VERSION ""

NS_ :

BS_:

BU_: FUSION CCU EOP_R BMS MCU_F Shifter EOP_F MCU_R

BO_ 1173 GW_IVI2: 64 FUSION
 SG_ AVM_parking_cancel : 505|2@0+ (1,0) [0|3] "" Vector__XXX
 SG_ AVM_parking_excute : 507|2@0+ (1,0) [0|3] "" Vector__XXX
 SG_ AVM_OFF_Rec_Butt : 508|1@0+ (1,0) [0|1] "" Vector__XXX
 SG_ IVI_AGSCloseSW : 511|2@0+ (1,0) [0|3] "" Vector__XXX
 SG_ IVI_LVChrgFuncSW : 497|2@0+ (1,0) [0|3] "" Vector__XXX
 SG_ IVI_PwrLockSW : 499|2@0+ (1,0) [0|3] "" Vector__XXX
 SG_ IVI_CoastDwSW : 501|2@0+ (1,0) [0|3] "" Vector__XXX
 SG_ IVI_ActvDmpDisabSW : 503|2@0+ (1,0) [0|3] "" Vector__XXX
 SG_ Roll_Mode_SW_Cmd : 473|2@0+ (1,0) [0|3] "" Vector__XXX
 SG_ TCS_SW_Cmd : 475|2@0+ (1,0) [0|3] "" Vector__XXX
 SG_ SLIF_BUTT : 477|2@0+ (1,0) [0|2] "" Vector__XXX
 SG_ Roll_Eng_Mode : 478|1@0+ (1,0) [0|1] "" Vector__XXX
 SG_ SOC_Limit_Set : 468|5@0+ (2,50) [50|100] "%" BMS
 SG_ CDL_Lock_Butt : 469|1@0+ (1,0) [0|1] "" Vector__XXX
 SG_ CDL_Unlock_Butt : 470|1@0+ (1,0) [0|1] "" Vector__XXX
 SG_ SOC_ADJ_BUTT : 471|1@0+ (1,0) [0|1] "" BMS
 SG_ AC_Chg_Cur_Set : 462|7@0+ (1,5) [5|132] "A" CCU,BMS
 SG_ IVI_ISA_OffsetSpd : 451|4@0+ (1,0) [0|14] "" Vector__XXX
 SG_ RoomLampMode : 455|1@0+ (1,0) [0|1] "" Vector__XXX
 SG_ NAVI_SpeedLimit : 444|5@0+ (1,0) [0|31] "km/h" Vector__XXX
 SG_ NAVI_RoadClass : 447|3@0+ (1,0) [0|7] "" Vector__XXX
 SG_ NAVI_Tollgate : 427|12@0+ (1,0) [0|2000] "m" Vector__XXX
 SG_ NAVI_LinkClass : 431|4@0+ (1,0) [0|15] "" Vector__XXX
 SG_ NAVI_Tunnel : 411|12@0+ (1,0) [0|2000] "m" Vector__XXX
 SG_ NAVI_ForwardLinkLevel : 415|4@0+ (1,0) [0|15] "" Vector__XXX
 SG_ SenstivityPosition : 403|4@0+ (1,0) [0|15] "" Vector__XXX
 SG_ AVM_Parking_mode : 407|4@0+ (1,0) [0|15] "" Vector__XXX
 SG_ Hood_Latch_SW : 393|2@0+ (1,0) [0|3] "" Vector__XXX
 SG_ RCTA_BUTT : 396|2@0+ (1,0) [0|3] "" Vector__XXX
 SG_ IVI_Pwroff_req : 397|1@0+ (1,0) [0|1] "" Vector__XXX
 SG_ IVI_Trigger_req : 398|1@0+ (1,0) [0|1] "" Vector__XXX
 SG_ AVM_Err_STA : 399|1@0+ (1,0) [0|1] "" Vector__XXX
 SG_ NAVI_Distance_info : 375|24@0+ (1,0) [0|1.6777215E7] "m" Vector__XXX
 SG_ IVI_Mute_Sta : 360|1@0+ (1,0) [0|1] "" Vector__XXX
 SG_ IVI_PTG_USSta_SW : 361|1@0+ (1,0) [0|1] "" Vector__XXX
 SG_ IVI_WI_MAIN_SW : 362|1@0+ (1,0) [0|1] "" Vector__XXX
 SG_ IVI_RR_Def_Req : 363|1@0+ (1,0) [0|1] "" Vector__XXX
 SG_ IVI_Night_Mode_Sta : 364|1@0+ (1,0) [0|1] "" Vector__XXX
 SG_ IVI_Status : 365|1@0+ (1,0) [0|1] "" Vector__XXX
 SG_ LVDAMute_BUTT : 367|2@0+ (1,0) [0|3] "" Vector__XXX
 SG_ CAAS_Sw : 353|2@0+ (1,0) [0|3] "" Vector__XXX
 SG_ DSEAT_entryfun_set : 354|1@0+ (1,0) [0|1] "" Vector__XXX
 SG_ DSEAT_anti_set : 355|1@0+ (1,0) [0|1] "" Vector__XXX
 SG_ TPMS_Res_Butt : 357|1@0+ (1,0) [0|1] "" Vector__XXX
 SG_ FollowMeSW : 358|1@0+ (1,0) [0|1] "" Vector__XXX
 SG_ SetUnlockSingle : 359|1@0+ (1,0) [0|1] "" Vector__XXX
 SG_ IVI_PTG_Mode_SW : 345|2@0+ (1,0) [0|3] "" Vector__XXX
 SG_ IVI_PTG_Sta_SW : 347|2@0+ (1,0) [0|3] "" Vector__XXX
 SG_ SLG_Sw : 349|2@0+ (1,0) [0|3] "" Vector__XXX
 SG_ FS_Off_Sw : 351|2@0+ (1,0) [0|3] "" Vector__XXX
 SG_ PSEAT_vent_req : 338|3@0+ (1,0) [0|7] "" Vector__XXX
 SG_ FFogLampSW : 339|1@0+ (1,0) [0|1] "" Vector__XXX
 SG_ DSEAT_vent_req : 342|3@0+ (1,0) [0|7] "" Vector__XXX
 SG_ RFogLampSW : 343|1@0+ (1,0) [0|1] "" Vector__XXX
 SG_ MFRD_N_Bright_Req : 334|7@0+ (1,0) [0|100] "%" Vector__XXX
 SG_ User_p_download : 335|1@0+ (1,0) [0|1] "" Vector__XXX
 SG_ HeadLampSW : 321|2@0+ (1,0) [0|3] "" Vector__XXX
 SG_ NAVI_State : 323|2@0+ (1,0) [0|3] "" Vector__XXX
 SG_ Wifi_Sta_IVI_TBOX : 327|4@0+ (1,0) [0|15] "" Vector__XXX
 SG_ IVI_Panel_Y_Coor : 307|12@0+ (1,0) [0|4095] "" Vector__XXX
 SG_ IVI_Panel_X_Coor : 303|12@0+ (1,0) [0|4095] "" Vector__XXX
 SG_ NAVI_Cam_Dist_info : 295|8@0+ (1,0) [0|255] "m" Vector__XXX
 SG_ OFF_AC_MODE : 282|3@0+ (1,0) [0|7] "" Vector__XXX
 SG_ IVI_PW_Mode_Req : 284|2@0+ (1,0) [0|3] "" Vector__XXX
 SG_ User_p_upload : 285|1@0+ (1,0) [0|1] "" Vector__XXX
 SG_ CameraWrn : 286|1@0+ (1,0) [0|1] "" Vector__XXX
 SG_ Wifi_Reset : 287|1@0+ (1,0) [0|1] "" Vector__XXX
 SG_ NAVI_Direction_STA : 279|8@0+ (1,0) [0|255] "" Vector__XXX
 SG_ IVI_Screen : 269|6@0+ (1,0) [0|62] "" Vector__XXX
 SG_ TurnSwTimeSet : 271|2@0+ (1,0) [0|3] "" Vector__XXX
 SG_ Pressure_unit : 263|8@0+ (1,0) [0|255] "" Vector__XXX
 SG_ Time_system : 255|8@0+ (1,0) [0|255] "" Vector__XXX
 SG_ NAVI_Speed_Limit_A : 241|2@0+ (1,0) [0|3] "" Vector__XXX
 SG_ Temperature_unit : 242|1@0+ (1,0) [0|1] "" Vector__XXX
 SG_ Distance_unit : 243|1@0+ (1,0) [0|1] "" Vector__XXX
 SG_ ESC_SW_Cmd : 245|2@0+ (1,0) [0|3] "" Vector__XXX
 SG_ IVI_Panel_Act : 246|1@0+ (1,0) [0|1] "" Vector__XXX
 SG_ sigHvacRearReq : 247|1@0+ (1,0) [0|1] "" Vector__XXX
 SG_ FCWMute_BUTT : 233|2@0+ (1,0) [0|3] "" Vector__XXX
 SG_ LKA_BUTT : 235|2@0+ (1,0) [0|3] "" Vector__XXX
 SG_ ODAMute_BUTT : 237|2@0+ (1,0) [0|3] "" Vector__XXX
 SG_ LDWMute_BUTT : 239|2@0+ (1,0) [0|3] "" Vector__XXX
 SG_ BSDMute_BUTT : 225|2@0+ (1,0) [0|3] "" Vector__XXX
 SG_ sigWindDirZon3Req : 228|3@0+ (1,0) [0|7] "" Vector__XXX
 SG_ sigAirIntenZon3Req : 219|4@0+ (1,0) [0|15] "" Vector__XXX
 SG_ sigAirIntenZon1Req : 223|4@0+ (1,0) [0|15] "" Vector__XXX
 SG_ AEB_BUTT : 209|2@0+ (1,0) [0|3] "" Vector__XXX
 SG_ sigSetTempZon3Req : 215|6@0+ (0.5,17) [17|32] "Deg^C" Vector__XXX
 SG_ sigSetTempZon2Req : 205|6@0+ (0.5,17) [17|32] "Deg^C" Vector__XXX
 SG_ sigRecircReq : 206|1@0+ (1,0) [0|1] "" Vector__XXX
 SG_ sigHvacReq : 207|1@0+ (1,0) [0|1] "" Vector__XXX
 SG_ sigSetTempZon1Req : 197|6@0+ (0.5,17) [17|32] "Deg^C" Vector__XXX
 SG_ sigHvacFrontReq : 198|1@0+ (1,0) [0|1] "" Vector__XXX
 SG_ sigDfrstReq : 199|1@0+ (1,0) [0|1] "" Vector__XXX
 SG_ GPS_LAT : 167|32@0+ (1,0) [0|4.294967295E9] "SECOND" Vector__XXX
 SG_ GPS_LONG : 135|32@0+ (1,0) [0|4.294967295E9] "" Vector__XXX
 SG_ L_Drv_ControlCommand : 126|7@0+ (1,0) [0|127] "%" Vector__XXX
 SG_ TPMS_Cali_Butt : 127|1@0+ (1,0) [0|1] "" Vector__XXX
 SG_ L_Pas_ControlCommand : 118|7@0+ (1,0) [0|127] "%" Vector__XXX
 SG_ IVI_Unlock_Chg_req : 119|1@0+ (1,0) [0|1] "" BMS
 SG_ L_RLD_ControlCommand : 110|7@0+ (1,0) [0|127] "%" Vector__XXX
 SG_ IVI_Stop_Chg_req : 111|1@0+ (1,0) [0|1] "" BMS
 SG_ L_RRD_ControlCommand : 102|7@0+ (1,0) [0|127] "%" Vector__XXX
 SG_ IVI_Start_Chg_req : 103|1@0+ (1,0) [0|1] "" BMS
 SG_ METER_Malfunc_Sta : 89|2@0+ (1,0) [0|2] "" Vector__XXX
 SG_ sigFootReq : 90|1@0+ (1,0) [0|1] "" Vector__XXX
 SG_ sigFaceReq : 91|1@0+ (1,0) [0|1] "" Vector__XXX
 SG_ Sched_Chg_Start : 92|1@0+ (1,0) [0|1] "" BMS
 SG_ Sched_Chg_wake : 93|1@0+ (1,0) [0|1] "" Vector__XXX
 SG_ Sched_Chg_butt : 94|1@0+ (1,0) [0|1] "" BMS
 SG_ Sched_Chg_Stop : 95|1@0+ (1,0) [0|1] "" BMS
 SG_ Sched_Chg_limit : 84|5@0+ (2,50) [50|100] "%" BMS
 SG_ Walkaway_Lock_SW : 8|1@0+ (1,0) [0|1] "" Vector__XXX
 SG_ Approach_Unlock_SW : 9|1@0+ (1,0) [0|1] "" Vector__XXX
 SG_ FalseNPrevent_SW : 10|1@0+ (1,0) [0|1] "" Vector__XXX
 SG_ IVI_CreepSW_Req : 11|1@0+ (1,0) [0|1] "" Vector__XXX
 SG_ IVI_PTG_Open_Height : 14|3@0+ (1,0) [0|7] "" Vector__XXX
 SG_ IVI_Req_V2L : 15|1@0+ (1,0) [0|1] "" BMS
 SG_ Perd_V2L : 3|4@0+ (1,0) [0|15] "" BMS
 SG_ SOC_V2LLimit : 7|4@0+ (5,20) [20|80] "%" BMS

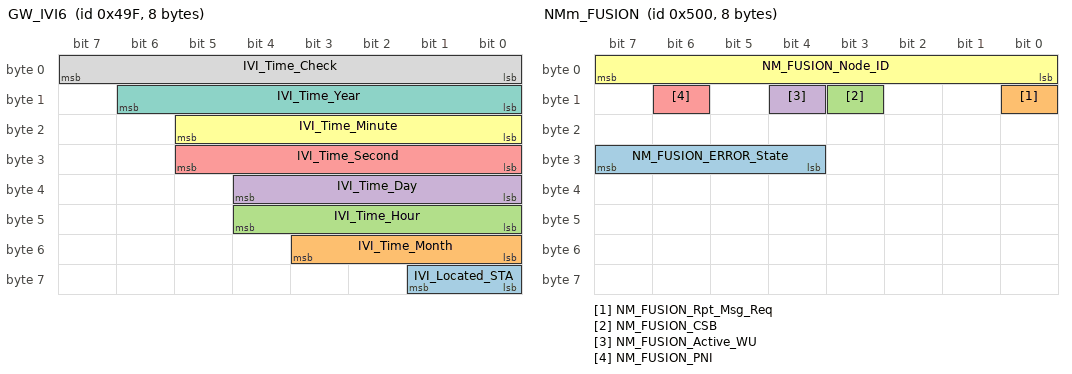
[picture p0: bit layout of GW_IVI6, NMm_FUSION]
BO_ 1183 GW_IVI6: 8 FUSION
 SG_ IVI_Located_STA : 57|2@0+ (1,0) [0|3] "" Vector__XXX
 SG_ IVI_Time_Month : 51|4@0+ (1,0) [0|12] "MONTH" CCU,EOP_R,BMS,MCU_F,Shifter,EOP_F,MCU_R
 SG_ IVI_Time_Hour : 44|5@0+ (1,0) [0|31] "HOUR" CCU,EOP_R,BMS,MCU_F,Shifter,EOP_F,MCU_R
 SG_ IVI_Time_Day : 36|5@0+ (1,0) [0|31] "DAY" CCU,EOP_R,BMS,MCU_F,Shifter,EOP_F,MCU_R
 SG_ IVI_Time_Second : 29|6@0+ (1,0) [0|63] "SECOND" CCU,EOP_R,BMS,MCU_F,Shifter,EOP_F,MCU_R
 SG_ IVI_Time_Minute : 21|6@0+ (1,0) [0|63] "MINUTE" CCU,EOP_R,BMS,MCU_F,Shifter,EOP_F,MCU_R
 SG_ IVI_Time_Year : 14|7@0+ (1,2000) [2000|2127] "YEAR" Vector__XXX
 SG_ IVI_Time_Check : 7|8@0+ (1,0) [0|255] "" CCU,EOP_R,BMS,Shifter,EOP_F

BO_ 1249 GW_TBOX3: 48 FUSION
 SG_ TBOX_SW_VER : 279|32@0+ (1,0) [0|4.294967295E9] "" Vector__XXX
 SG_ TBOX_HW_VER : 231|32@0+ (1,0) [0|4.294967295E9] "" Vector__XXX
 SG_ ReserveChargeOn_Minute : 221|6@0+ (1,0) [0|59] "MINUTE" BMS
 SG_ ReserveChargeOn_Hour : 210|5@0+ (1,0) [0|23] "HOUR" BMS
 SG_ ReserveChargeOn_Day : 215|5@0+ (1,0) [0|31] "DAY" BMS
 SG_ ReserveChargeOn_Month : 203|4@0+ (1,0) [0|12] "MONTH" BMS
 SG_ ReserveChargeOn_Year : 194|7@0+ (1,2000) [2000|2099] "YEAR" BMS
 SG_ ReserveChargeOFF_Minute : 189|6@0+ (1,0) [0|59] "MINUTE" BMS
 SG_ ReserveChargeOFF_Hour : 178|5@0+ (1,0) [0|23] "HOUR" BMS
 SG_ ReserveChargeOFF_Day : 183|5@0+ (1,0) [0|31] "DAY" BMS
 SG_ ReserveChargeOFF_Month : 171|4@0+ (1,0) [0|12] "MONTH" BMS
 SG_ ReserveChargeOFF_Year : 162|7@0+ (1,2000) [2000|2099] "YEAR" BMS
 SG_ Charge_Percent_Set : 159|8@0+ (1,0) [0|100] "%" BMS

BO_ 1280 NMm_FUSION: 8 FUSION
 SG_ NM_FUSION_ERROR_State : 31|4@0+ (1,0) [0|8] "" CCU,EOP_R,BMS,MCU_F,Shifter,EOP_F,MCU_R
 SG_ NM_FUSION_Rpt_Msg_Req : 8|1@0+ (1,0) [0|1] "" CCU,EOP_R,BMS,MCU_F,Shifter,EOP_F,MCU_R
 SG_ NM_FUSION_CSB : 11|1@0+ (1,0) [0|1] "" CCU,EOP_R,BMS,MCU_F,Shifter,EOP_F,MCU_R
 SG_ NM_FUSION_Active_WU : 12|1@0+ (1,0) [0|1] "" CCU,EOP_R,BMS,MCU_F,Shifter,EOP_F,MCU_R
 SG_ NM_FUSION_PNI : 14|1@0+ (1,0) [0|1] "" CCU,EOP_R,BMS,MCU_F,Shifter,EOP_F,MCU_R
 SG_ NM_FUSION_Node_ID : 7|8@0+ (1,0) [0|127] "" CCU,EOP_R,BMS,MCU_F,Shifter,EOP_F,MCU_R

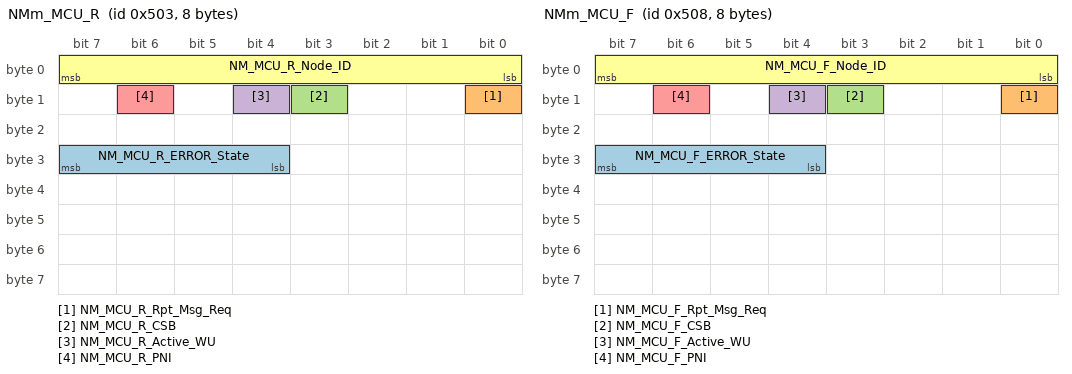
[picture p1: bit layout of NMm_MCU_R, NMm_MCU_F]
BO_ 1283 NMm_MCU_R: 8 MCU_R
 SG_ NM_MCU_R_ERROR_State : 31|4@0+ (1,0) [0|8] "" FUSION
 SG_ NM_MCU_R_Rpt_Msg_Req : 8|1@0+ (1,0) [0|1] "" FUSION
 SG_ NM_MCU_R_CSB : 11|1@0+ (1,0) [0|1] "" FUSION
 SG_ NM_MCU_R_Active_WU : 12|1@0+ (1,0) [0|1] "" FUSION
 SG_ NM_MCU_R_PNI : 14|1@0+ (1,0) [0|1] "" FUSION
 SG_ NM_MCU_R_Node_ID : 7|8@0+ (1,0) [0|127] "" FUSION

BO_ 1288 NMm_MCU_F: 8 MCU_F
 SG_ NM_MCU_F_ERROR_State : 31|4@0+ (1,0) [0|8] "" FUSION
 SG_ NM_MCU_F_Rpt_Msg_Req : 8|1@0+ (1,0) [0|1] "" FUSION
 SG_ NM_MCU_F_CSB : 11|1@0+ (1,0) [0|1] "" FUSION
 SG_ NM_MCU_F_Active_WU : 12|1@0+ (1,0) [0|1] "" FUSION
 SG_ NM_MCU_F_PNI : 14|1@0+ (1,0) [0|1] "" FUSION
 SG_ NM_MCU_F_Node_ID : 7|8@0+ (1,0) [0|127] "" FUSION

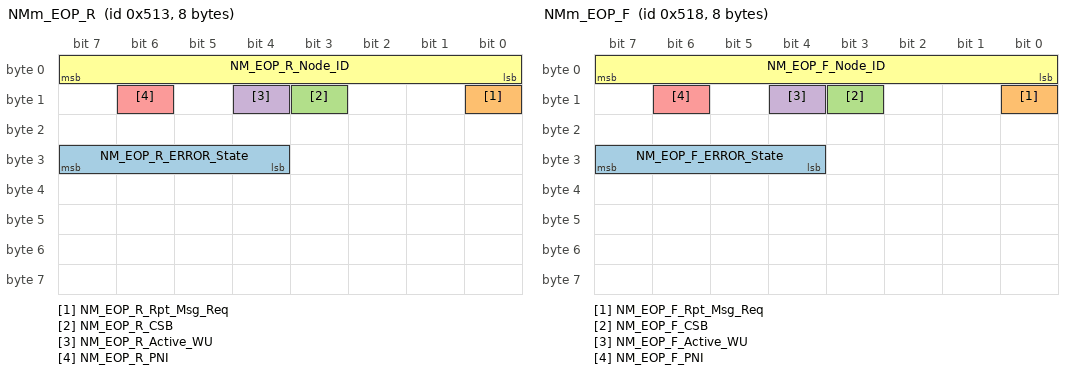
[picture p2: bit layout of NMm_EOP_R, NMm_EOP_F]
BO_ 1299 NMm_EOP_R: 8 EOP_R
 SG_ NM_EOP_R_ERROR_State : 31|4@0+ (1,0) [0|8] "" FUSION
 SG_ NM_EOP_R_Rpt_Msg_Req : 8|1@0+ (1,0) [0|1] "" FUSION
 SG_ NM_EOP_R_CSB : 11|1@0+ (1,0) [0|1] "" FUSION
 SG_ NM_EOP_R_Active_WU : 12|1@0+ (1,0) [0|1] "" FUSION
 SG_ NM_EOP_R_PNI : 14|1@0+ (1,0) [0|1] "" FUSION
 SG_ NM_EOP_R_Node_ID : 7|8@0+ (1,0) [0|127] "" FUSION

BO_ 1304 NMm_EOP_F: 8 EOP_F
 SG_ NM_EOP_F_ERROR_State : 31|4@0+ (1,0) [0|8] "" FUSION
 SG_ NM_EOP_F_Rpt_Msg_Req : 8|1@0+ (1,0) [0|1] "" FUSION
 SG_ NM_EOP_F_CSB : 11|1@0+ (1,0) [0|1] "" FUSION
 SG_ NM_EOP_F_Active_WU : 12|1@0+ (1,0) [0|1] "" FUSION
 SG_ NM_EOP_F_PNI : 14|1@0+ (1,0) [0|1] "" FUSION
 SG_ NM_EOP_F_Node_ID : 7|8@0+ (1,0) [0|127] "" FUSION

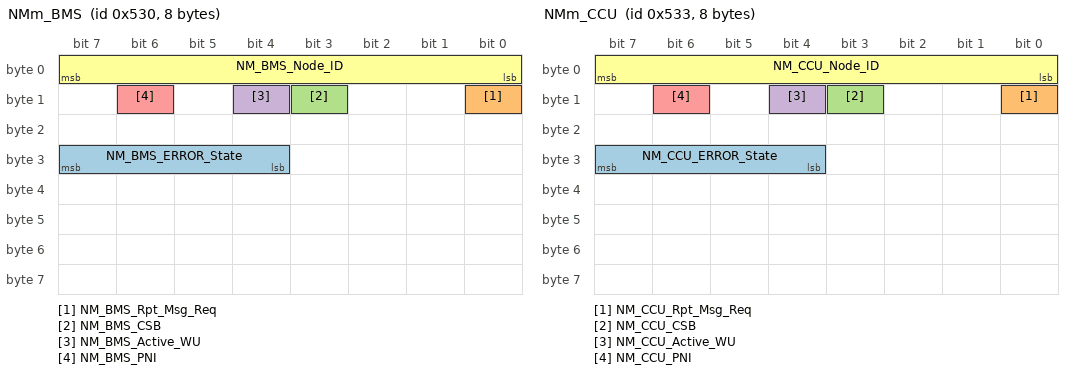
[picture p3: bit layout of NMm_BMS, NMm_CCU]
BO_ 1328 NMm_BMS: 8 BMS
 SG_ NM_BMS_ERROR_State : 31|4@0+ (1,0) [0|8] "" FUSION
 SG_ NM_BMS_Rpt_Msg_Req : 8|1@0+ (1,0) [0|1] "" FUSION
 SG_ NM_BMS_CSB : 11|1@0+ (1,0) [0|1] "" FUSION
 SG_ NM_BMS_Active_WU : 12|1@0+ (1,0) [0|1] "" FUSION
 SG_ NM_BMS_PNI : 14|1@0+ (1,0) [0|1] "" FUSION
 SG_ NM_BMS_Node_ID : 7|8@0+ (1,0) [0|127] "" FUSION

BO_ 1331 NMm_CCU: 8 CCU
 SG_ NM_CCU_ERROR_State : 31|4@0+ (1,0) [0|8] "" FUSION
 SG_ NM_CCU_Rpt_Msg_Req : 8|1@0+ (1,0) [0|1] "" FUSION
 SG_ NM_CCU_CSB : 11|1@0+ (1,0) [0|1] "" FUSION
 SG_ NM_CCU_Active_WU : 12|1@0+ (1,0) [0|1] "" FUSION
 SG_ NM_CCU_PNI : 14|1@0+ (1,0) [0|1] "" FUSION
 SG_ NM_CCU_Node_ID : 7|8@0+ (1,0) [0|127] "" FUSION

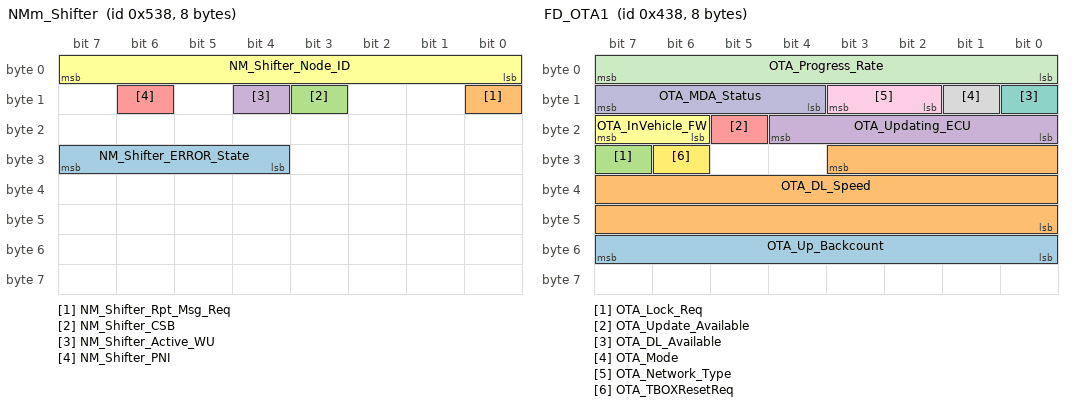
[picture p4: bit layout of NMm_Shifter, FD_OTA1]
BO_ 1336 NMm_Shifter: 8 Shifter
 SG_ NM_Shifter_ERROR_State : 31|4@0+ (1,0) [0|8] "" FUSION
 SG_ NM_Shifter_Rpt_Msg_Req : 8|1@0+ (1,0) [0|1] "" FUSION
 SG_ NM_Shifter_CSB : 11|1@0+ (1,0) [0|1] "" FUSION
 SG_ NM_Shifter_Active_WU : 12|1@0+ (1,0) [0|1] "" FUSION
 SG_ NM_Shifter_PNI : 14|1@0+ (1,0) [0|1] "" FUSION
 SG_ NM_Shifter_Node_ID : 7|8@0+ (1,0) [0|127] "" FUSION

BO_ 1539 DiagRespFromMCU_R: 8 MCU_R
 SG_ DiagRespFromMCU_R : 7|64@0+ (1,0) [0|0] "" FUSION

BO_ 1544 DiagRespFromMCU_F: 8 MCU_F
 SG_ DiagRespFromMCU_F : 7|64@0+ (1,0) [0|0] "" FUSION

BO_ 1555 DiagRespFromEOP_R: 8 EOP_R
 SG_ DiagRespFromEOP_R : 7|64@0+ (1,0) [0|0] "" FUSION

BO_ 1560 DiagRespFromEOP_F: 8 EOP_F
 SG_ DiagRespFromEOP_F : 7|64@0+ (1,0) [0|0] "" FUSION

BO_ 1584 DiagRespFromBMS: 8 BMS
 SG_ DiagRespFromBMS : 7|64@0+ (1,0) [0|0] "" FUSION

BO_ 1587 DiagRespFromCCU: 8 CCU
 SG_ DiagRespFromCCU : 7|64@0+ (1,0) [0|0] "" FUSION

BO_ 1592 DiagRespFromShifter: 8 Shifter
 SG_ DiagRespFromShifter : 7|64@0+ (1,0) [0|0] "" FUSION

BO_ 1667 DiagPhysReqToMCU_R: 8 FUSION
 SG_ DiagPhysReqToMCU_R : 7|64@0+ (1,0) [0|0] "" MCU_R

BO_ 1672 DiagPhysReqToMCU_F: 8 FUSION
 SG_ DiagPhysReqToMCU_F : 7|64@0+ (1,0) [0|0] "" MCU_F

BO_ 1683 DiagPhysReqToEOP_R: 8 FUSION
 SG_ DiagPhysReqToEOP_R : 7|64@0+ (1,0) [0|0] "" EOP_R

BO_ 1688 DiagPhysReqToEOP_F: 8 FUSION
 SG_ DiagPhysReqToEOP_F : 7|64@0+ (1,0) [0|0] "" EOP_F

BO_ 1712 DiagPhysReqToBMS: 8 FUSION
 SG_ DiagPhysReqToBMS : 7|64@0+ (1,0) [0|0] "" BMS

BO_ 1715 DiagPhysReqToCCU: 8 FUSION
 SG_ DiagPhysReqToCCU : 7|64@0+ (1,0) [0|0] "" CCU

BO_ 1720 DiagPhysReqToShifter: 8 FUSION
 SG_ DiagPhysReqToShifter : 7|64@0+ (1,0) [0|0] "" Shifter

BO_ 2000 DiagFuncReqFT: 8 FUSION
 SG_ DiagFuncReqFT : 7|64@0+ (1,0) [0|0] "" CCU,EOP_R,BMS,MCU_F,Shifter,EOP_F,MCU_R

BO_ 1080 FD_OTA1: 8 FUSION
 SG_ OTA_Up_Backcount : 55|8@0+ (1,0) [0|122] "" Vector__XXX
 SG_ OTA_DL_Speed : 27|20@0+ (1,0) [0|1048575] "Kb/s" Vector__XXX
 SG_ OTA_Lock_Req : 31|1@0+ (1,0) [0|1] "" Vector__XXX
 SG_ OTA_Updating_ECU : 20|5@0+ (1,0) [0|30] "" Vector__XXX
 SG_ OTA_Update_Available : 21|1@0+ (1,0) [0|1] "" Vector__XXX
 SG_ OTA_InVehicle_FW : 23|2@0+ (1,0) [0|2] "" Vector__XXX
 SG_ OTA_DL_Available : 8|1@0+ (1,0) [0|1] "" Vector__XXX
 SG_ OTA_Mode : 9|1@0+ (1,0) [0|1] "" BMS,Shifter
 SG_ OTA_Network_Type : 11|2@0+ (1,0) [0|3] "" Vector__XXX
 SG_ OTA_MDA_Status : 15|4@0+ (1,0) [0|14] "" Vector__XXX
 SG_ OTA_Progress_Rate : 7|8@0+ (1,0) [0|102] "" Vector__XXX
 SG_ OTA_TBOXResetReq : 30|1@0+ (1,0) [0|1] "" Vector__XXX

BO_ 552 GW_ZoneFR1: 20 FUSION
 SG_ CCV4_MoveEnable : 152|1@0+ (1,0) [0|1] "" Vector__XXX
 SG_ CCV4_ReqMovePos : 153|1@0+ (1,0) [0|1] "" Vector__XXX
 SG_ EWP1_Default_Operation_EWP_Rq : 154|1@0+ (1,0) [0|1] "" Vector__XXX
 SG_ EWP3_Default_Operation_EWP_Rq : 155|1@0+ (1,0) [0|1] "" Vector__XXX
 SG_ BDC_1_MoveEnable : 156|1@0+ (1,0) [0|1] "" Vector__XXX
 SG_ EWP2_Default_Operation_EWP_Rq : 157|1@0+ (1,0) [0|1] "" Vector__XXX
 SG_ EXV_Cmd_Move_Enbl : 158|1@0+ (1,0) [0|1] "" Vector__XXX
 SG_ EXV2_Cmd_Move_Enbl : 159|1@0+ (1,0) [0|1] "" Vector__XXX
 SG_ EXV2_Cmd_Init_Rq : 146|3@0+ (1,0) [0|1] "" Vector__XXX
 SG_ EXV_Cmd_Init_Rq : 149|3@0+ (1,0) [0|1] "" Vector__XXX
 SG_ EWP1_RPM_Target_EWP_Rq : 143|8@0+ (1,0) [0|254] "" Vector__XXX
 SG_ EWP3_RPM_Target_EWP_Rq : 135|8@0+ (1,0) [0|254] "" Vector__XXX
 SG_ BDC_1_ReqMovePos : 127|8@0+ (0.392,0) [0|99.96] "" Vector__XXX
 SG_ EWP2_RPM_Target_EWP_Rq : 119|8@0+ (1,0) [0|254] "" Vector__XXX
 SG_ EXV_Cmd_Set_Rq : 103|16@0+ (1,0) [0|576] "" Vector__XXX
 SG_ EXV2_Cmd_Set_Rq : 87|16@0+ (1,0) [0|576] "" Vector__XXX
 SG_ FWiperAS : 56|1@0+ (1,0) [0|1] "" Vector__XXX
 SG_ FWiperProtection : 57|1@0+ (1,0) [0|1] "" Vector__XXX
 SG_ ChargeInletLockSta : 58|1@0+ (1,0) [0|1] "" BMS
 SG_ FLTurnLampC : 55|8@0+ (10,0) [0|2550] "mA" Vector__XXX
 SG_ FRTurnLampC : 47|8@0+ (10,0) [0|2550] "mA" Vector__XXX
 SG_ AGS_Actuator_Blocked : 8|1@0+ (1,0) [0|1] "" Vector__XXX
 SG_ AGS_Actuator_Fault : 9|1@0+ (1,0) [0|1] "" Vector__XXX
 SG_ AGS_Calibration_Active : 10|1@0+ (1,0) [0|1] "" Vector__XXX
 SG_ AGS_Calibration_Indicated : 11|1@0+ (1,0) [0|1] "" Vector__XXX
 SG_ AGS_Electrical_Error : 12|1@0+ (1,0) [0|1] "" Vector__XXX
 SG_ AGS_Sensor_Error : 13|1@0+ (1,0) [0|1] "" Vector__XXX
 SG_ AGS_Temperature_Error : 14|1@0+ (1,0) [0|1] "" Vector__XXX
 SG_ AGS_Low_Voltage_Error : 15|1@0+ (1,0) [0|1] "" Vector__XXX
 SG_ AGS_Actual_Position : 7|8@0+ (1,0) [0|240] "" Vector__XXX
 SG_ AGS_LINResponse_Error : 23|1@0+ (1,0) [0|1] "" Vector__XXX
 SG_ AGS_Calibration_Enabled : 22|1@0+ (1,0) [0|1] "" Vector__XXX
 SG_ AGS_Position_Request : 31|8@0+ (1,0) [0|255] "" Vector__XXX

BO_ 496 FD_VCU0: 64 FUSION
 SG_ SysPwrSta : 7|4@0+ (1,0) [0|15] "" Vector__XXX
 SG_ PowerUpState : 15|4@0+ (1,0) [0|7] "" Vector__XXX
 SG_ PowerUpFault : 11|4@0+ (1,0) [0|7] "" Vector__XXX
 SG_ PowerDownState : 22|3@0+ (1,0) [0|7] "" Vector__XXX
 SG_ PowerDownFault : 19|4@0+ (1,0) [0|7] "" Vector__XXX
 SG_ PwrStaSelect : 31|2@0+ (1,0) [0|3] "" Vector__XXX
 SG_ PwrStaConstraint : 29|3@0+ (1,0) [0|4] "" Vector__XXX
 SG_ TCountSta : 26|2@0+ (1,0) [0|2] "" Vector__XXX
 SG_ PwrUpReq : 39|2@0+ (1,0) [0|2] "" Vector__XXX
 SG_ PwrDownReq : 37|2@0+ (1,0) [0|2] "" Vector__XXX
 SG_ Rr_TqSource : 35|4@0+ (1,0) [0|9] "" Vector__XXX
 SG_ Fr_TqSource : 47|4@0+ (1,0) [0|9] "" Vector__XXX
 SG_ LVBattVoltSta : 43|2@0+ (1,0) [0|3] "" Vector__XXX
 SG_ HVTHCMSysAvail : 41|2@0+ (1,0) [0|3] "" Vector__XXX
 SG_ VehHVPwrAvail4THCM : 55|8@0+ (50,0) [0|12650] "W" Vector__XXX
 SG_ VCUBrkSWSta : 63|2@0+ (1,0) [0|2] "" Vector__XXX
 SG_ VCUFLDoorSta : 61|1@0+ (1,0) [0|1] "" Vector__XXX
 SG_ VCUFRDoorSta : 60|1@0+ (1,0) [0|1] "" Vector__XXX
 SG_ VCURLDoorSta : 59|1@0+ (1,0) [0|1] "" Vector__XXX
 SG_ VCURRDoorSta : 58|1@0+ (1,0) [0|1] "" Vector__XXX
 SG_ SysAllowReadySta : 57|1@0+ (1,0) [0|1] "" Vector__XXX
 SG_ HVRlyOpFail : 56|1@0+ (1,0) [0|1] "" Vector__XXX
 SG_ MCUActDisFail : 71|1@0+ (1,0) [0|1] "" Vector__XXX
 SG_ PwrStaONTOIVIPopReq : 70|1@0+ (1,0) [0|1] "" Vector__XXX
 SG_ PwrStaTOSta : 69|1@0+ (1,0) [0|1] "" Vector__XXX
 SG_ PwrStaONTOIVIPopT : 67|12@0+ (1,0) [0|4095] "SECOND" Vector__XXX
 SG_ SchedChgTOSta : 87|1@0+ (1,0) [0|1] "" Vector__XXX
 SG_ SilentChkAllowSleep : 86|1@0+ (1,0) [0|1] "" Vector__XXX
 SG_ LVSilentChrgSta : 85|2@0+ (1,0) [0|3] "" Vector__XXX
 SG_ LVSilentChrgLv : 83|2@0+ (1,0) [0|3] "" Vector__XXX
 SG_ LVSilentChrgReq : 81|1@0+ (1,0) [0|1] "" Vector__XXX
 SG_ TimerAllowSleep : 80|1@0+ (1,0) [0|1] "" Vector__XXX
 SG_ PMMAllowECUSleep : 95|1@0+ (1,0) [0|1] "" Vector__XXX
 SG_ LVChrgHoldTAct : 91|12@0+ (1,0) [0|4095] "SECOND" Vector__XXX
 SG_ LVBattChrgtimeAct : 107|12@0+ (1,0) [0|4095] "SECOND" Vector__XXX
 SG_ EVCCAplusPwrUpReq : 94|1@0+ (1,0) [0|1] "" Vector__XXX
 SG_ FDADC12VDetAvg : 127|8@0+ (0.1,0) [0|25.5] "V" Vector__XXX
 SG_ FDC_VMC_ActStESCYaw_Sta : 215|16@0+ (0.01,-300) [-300|300] "Deg/s" Vector__XXX
 SG_ FDC_VMC_LongAcc_Sta : 151|16@0+ (0.001,-20) [-20|20] "G's" Vector__XXX
 SG_ FDC_VCU_VehActSpd_Sta : 167|16@0+ (0.01,-300) [-300|300] "km/h" Vector__XXX
 SG_ FDC_VCU_ActMaxSlideRate_Sta : 183|16@0+ (0.01,-150) [-150|150] "%" Vector__XXX
 SG_ FDC_VCU_SlideRegenLimTq_Sta : 199|16@0+ (0.5,-5300) [-5300|5300] "Nm" Vector__XXX
 SG_ FDADC12VDet : 135|8@0+ (0.1,0) [0|25.5] "V" Vector__XXX
 SG_ FDC_VCU_DTCCarousel_Sta : 143|8@0+ (1,0) [0|255] "" Vector__XXX
 SG_ FDC_VCU_VehMalfunLevel_Sta : 3|4@0+ (1,0) [0|15] "" Vector__XXX
 SG_ FDC_VCU_RWDRDCActive_Sta : 93|2@0+ (1,0) [0|3] "" Vector__XXX
 SG_ FDC_VCU_AllowMovThd_OTA_Sta : 111|2@0+ (1,0) [0|3] "" Vector__XXX
 SG_ FDC_VCU_PwrReq_OTA_Sta : 109|2@0+ (1,0) [0|3] "" Vector__XXX
 SG_ FDC_VCU_RegenTqLimitEn_Sta : 23|1@0+ (1,0) [0|1] "" Vector__XXX
 SG_ FDC_VCU_ForceP_Cmd : 24|1@0+ (1,0) [0|1] "" Vector__XXX
 SG_ FDC_VMC_AntiSpdLimEn_Sta : 68|1@0+ (1,0) [0|1] "" Vector__XXX

CM_ SG_ 1173 AVM_parking_cancel "auto parking cancel";
CM_ SG_ 1173 AVM_parking_excute "confirm and start to auto parking";
CM_ SG_ 1173 AVM_OFF_Rec_Butt "AVM KEYOFF Recording Button";
CM_ SG_ 1173 IVI_AGSCloseSW "IVI AGS close switch";
CM_ SG_ 1173 IVI_LVChrgFuncSW "IVI LV Charging function switch";
CM_ SG_ 1173 IVI_PwrLockSW "IVI Power State Lock Switch";
CM_ SG_ 1173 IVI_CoastDwSW "IVI Coastdown switch";
CM_ SG_ 1173 IVI_ActvDmpDisabSW "IVI Active Damping Disable Switch";
CM_ SG_ 1173 Roll_Mode_SW_Cmd "Roll Mode Switch command";
CM_ SG_ 1173 TCS_SW_Cmd "TCS Switch command";
CM_ SG_ 1173 SLIF_BUTT "SLIF  ON/OFF Buttom";
CM_ SG_ 1173 Roll_Eng_Mode "Roll Engine Mode";
CM_ SG_ 1173 SOC_Limit_Set "SOC Charging Limitation Setting";
CM_ SG_ 1173 CDL_Lock_Butt "Central Door Lock_LOCK_Button";
CM_ SG_ 1173 CDL_Unlock_Butt "Central Door Lock_UNLOCK_Button";
CM_ SG_ 1173 SOC_ADJ_BUTT "SOC Charging Limitation Adjust Button";
CM_ SG_ 1173 AC_Chg_Cur_Set "AC Charging Current Setting";
CM_ SG_ 1173 IVI_ISA_OffsetSpd "IVI ISA Offset speed";
CM_ SG_ 1173 RoomLampMode "Room lampt on/off connected with car door open/close";
CM_ SG_ 1173 NAVI_SpeedLimit "Information for Current Link Speed Limit expressed as km/h or mph";
CM_ SG_ 1173 NAVI_RoadClass "Information for Road Class";
CM_ SG_ 1173 NAVI_Tollgate "Information for Tollgate exist (Exist information shall be informed 500m ahead)";
CM_ SG_ 1173 NAVI_LinkClass "Information for Link Class Value of Segment";
CM_ SG_ 1173 NAVI_Tunnel "Information for Tunnel exist (Exist information shall be informed 500m ahead)";
CM_ SG_ 1173 NAVI_ForwardLinkLevel "Information for Forward Link Level in Freeway (Change information shall be informed 500m ahead)";
CM_ SG_ 1173 SenstivityPosition "wiper Senstivity Position";
CM_ SG_ 1173 AVM_Parking_mode "AVM_Parking Mode";
CM_ SG_ 1173 Hood_Latch_SW "Hood Latch Switch";
CM_ SG_ 1173 RCTA_BUTT "RCTA ON/OFF Button";
CM_ SG_ 1173 IVI_Pwroff_req "IVI Power off request";
CM_ SG_ 1173 IVI_Trigger_req "IVI Trigger VCU to Ready request";
CM_ SG_ 1173 AVM_Err_STA "AVM Error Status";
CM_ SG_ 1173 NAVI_Distance_info "NAVI Distance Information";
CM_ SG_ 1173 IVI_Mute_Sta "IVI Mute status";
CM_ SG_ 1173 IVI_PTG_USSta_SW "Power Tail Gate Ultrasonic On/Off Switch";
CM_ SG_ 1173 IVI_WI_MAIN_SW "IVI Wiper Maintance_Switch";
CM_ SG_ 1173 IVI_RR_Def_Req "IVI Rear Deffogger Status";
CM_ SG_ 1173 IVI_Night_Mode_Sta "IVI Night Mode Status";
CM_ SG_ 1173 IVI_Status "IVI Status";
CM_ SG_ 1173 LVDAMute_BUTT "LDW Mute Buttom";
CM_ SG_ 1173 CAAS_Sw "Collision Avoidance Assistance System Switch Status";
CM_ SG_ 1173 DSEAT_entryfun_set "Driver Seat Entry on/off request";
CM_ SG_ 1173 DSEAT_anti_set "Driver Seat Antitheft on/off request";
CM_ SG_ 1173 TPMS_Res_Butt "TPMS_Reset_button";
CM_ SG_ 1173 FollowMeSW "Follow Me Home SW";
CM_ SG_ 1173 SetUnlockSingle "Single Set Unlock DOOR SETTING";
CM_ SG_ 1173 IVI_PTG_Mode_SW "Power Tail Gate Manual and Automatic mode Switch";
CM_ SG_ 1173 IVI_PTG_Sta_SW "Power Tail Gate Open and Close Switch";
CM_ SG_ 1173 SLG_Sw "Smart liftgate Switch Status";
CM_ SG_ 1173 FS_Off_Sw "F_USS Switch Status";
CM_ SG_ 1173 PSEAT_vent_req "Passenger Seat Ventilate request
0= No Request,
1= Vent1,
2= Vent2,
3= Vent3,
4= Off";
CM_ SG_ 1173 FFogLampSW "Front Fog Lamp Switch";
CM_ SG_ 1173 DSEAT_vent_req "Driver Seat ventilate request";
CM_ SG_ 1173 RFogLampSW "Rear Fog Lamp Switch";
CM_ SG_ 1173 MFRD_N_Bright_Req "MFRD night Brightness setting";
CM_ SG_ 1173 User_p_download "User profile download";
CM_ SG_ 1173 HeadLampSW "Head Lamp Switch";
CM_ SG_ 1173 NAVI_State "Information for Navigation Status";
CM_ SG_ 1173 Wifi_Sta_IVI_TBOX "Wifi signal status between IVI and TBOX";
CM_ SG_ 1173 IVI_Panel_Y_Coor "IVI Touch Panel Y coordinate";
CM_ SG_ 1173 IVI_Panel_X_Coor "IVI Touch Panel X coordinate";
CM_ SG_ 1173 NAVI_Cam_Dist_info "Navigation speed camera distance information";
CM_ SG_ 1173 OFF_AC_MODE "OFF AC MODE";
CM_ SG_ 1173 IVI_PW_Mode_Req "IVI Power Mode require";
CM_ SG_ 1173 User_p_upload "User profile upload";
CM_ SG_ 1173 CameraWrn "Speed cameras Warming";
CM_ SG_ 1173 Wifi_Reset "Wifi Reset between VIG and OBU";
CM_ SG_ 1173 NAVI_Direction_STA "NAVI Direction Status";
CM_ SG_ 1173 IVI_Screen "IVI Screen
0x1d~0x3E:undefined";
CM_ SG_ 1173 TurnSwTimeSet "turning switch flash time set";
CM_ SG_ 1173 Pressure_unit "Pressure unit";
CM_ SG_ 1173 Time_system "Time system";
CM_ SG_ 1173 NAVI_Speed_Limit_A "NAVI Speed Limitation Applicable";
CM_ SG_ 1173 Temperature_unit "Temperature unit";
CM_ SG_ 1173 Distance_unit "Distance unit";
CM_ SG_ 1173 ESC_SW_Cmd "ESC ON/OFF Buttom";
CM_ SG_ 1173 IVI_Panel_Act "IVI Touch Panel Active";
CM_ SG_ 1173 sigHvacRearReq "Request for operation for the rear HVAC (ON / OFF)";
CM_ SG_ 1173 FCWMute_BUTT "FCW Mute Buttom";
CM_ SG_ 1173 LKA_BUTT "LKA  ON/OFF Buttom";
CM_ SG_ 1173 ODAMute_BUTT "ODA Mute Buttom";
CM_ SG_ 1173 LDWMute_BUTT "LDW Mute Buttom";
CM_ SG_ 1173 BSDMute_BUTT "BSD Mute Buttom";
CM_ SG_ 1173 sigWindDirZon3Req "Request to HVAC Wind Direction Zone 3. 
Feed, Body and/or Auto";
CM_ SG_ 1173 sigAirIntenZon3Req "Request to HVAC FAN Level/Air Intensirty: 0-Max or Auto for zone 3
0xb~0xE:Reserved
0xb~0xE:Reserved
0xb~0xE:Reserved";
CM_ SG_ 1173 sigAirIntenZon1Req "Request to HVAC FAN Level/Air Intensirty: 0-Max or Auto for zone 1
0xb~0xE:Reserved
0xb~0xE:Reserved
0xb~0xE:Reserved";
CM_ SG_ 1173 AEB_BUTT "AEB  ON/OFF Buttom";
CM_ SG_ 1173 sigSetTempZon3Req "Temperature setpoint  for HVAC Zone 3";
CM_ SG_ 1173 sigSetTempZon2Req "Temperature setpoint  for HVAC Zone 2";
CM_ SG_ 1173 sigRecircReq "Recirculation request for the HVAC (ON / AUTO)";
CM_ SG_ 1173 sigHvacReq "Request for operation for the HVAC (ON / OFF)";
CM_ SG_ 1173 sigSetTempZon1Req "Temperature setpoint  for HVAC Zone 1";
CM_ SG_ 1173 sigHvacFrontReq "Request for operation for the front HVAC (ON / OFF)";
CM_ SG_ 1173 sigDfrstReq "Defrost request for the HVAC (ON / AUTO)";
CM_ SG_ 1173 GPS_LAT "GPS Location_Latitude";
CM_ SG_ 1173 GPS_LONG "GPS Location_Longitude";
CM_ SG_ 1173 L_Drv_ControlCommand "Driver window control command";
CM_ SG_ 1173 TPMS_Cali_Butt "TPMS tire calibrate button";
CM_ SG_ 1173 L_Pas_ControlCommand "Passenger window control command";
CM_ SG_ 1173 IVI_Unlock_Chg_req "IVI unlock Charging port Request";
CM_ SG_ 1173 L_RLD_ControlCommand "Rear Left window control command";
CM_ SG_ 1173 IVI_Stop_Chg_req "IVI Stop Charging Request";
CM_ SG_ 1173 L_RRD_ControlCommand "Rear Right  window control command";
CM_ SG_ 1173 IVI_Start_Chg_req "IVI Start Charging Request";
CM_ SG_ 1173 METER_Malfunc_Sta "Meter Malfunction Status";
CM_ SG_ 1173 sigFootReq "FOOT BLOWER REQUEST";
CM_ SG_ 1173 sigFaceReq "FACE BLOWER REQUEST";
CM_ SG_ 1173 Sched_Chg_Start "Scheduled Charging Start";
CM_ SG_ 1173 Sched_Chg_wake "Scheduled Charging wake up";
CM_ SG_ 1173 Sched_Chg_butt "Scheduled Charging Button";
CM_ SG_ 1173 Sched_Chg_Stop "Scheduled Charging stop";
CM_ SG_ 1173 Sched_Chg_limit "Scheduled Charging charging limit";
CM_ SG_ 1173 Walkaway_Lock_SW "Lock when walking away";
CM_ SG_ 1173 Approach_Unlock_SW "Unlock when approaching Switch";
CM_ SG_ 1173 FalseNPrevent_SW "Prevent FALSE turn GEAR into N";
CM_ SG_ 1173 IVI_CreepSW_Req "IVI Creep On/Off Switch Request";
CM_ SG_ 1173 IVI_PTG_Open_Height "IVI 'PTG Open Height' Menu Status";
CM_ SG_ 1173 IVI_Req_V2L "IVI require V2L on/off";
CM_ SG_ 1173 Perd_V2L "V2L Period Setting";
CM_ SG_ 1173 SOC_V2LLimit "SOC V2LLimitation";
CM_ SG_ 1183 IVI_Located_STA "IVI_GPS Satellite Located status";
CM_ SG_ 1183 IVI_Time_Month "IVI_GPS Satellite Time_Month";
CM_ SG_ 1183 IVI_Time_Hour "IVI_GPS Satellite Time_Hour";
CM_ SG_ 1183 IVI_Time_Day "IVI_GPS Satellite Time_Day";
CM_ SG_ 1183 IVI_Time_Second "IVI_GPS Satellite Time_Second";
CM_ SG_ 1183 IVI_Time_Minute "IVI_GPS Satellite Time_Minute";
CM_ SG_ 1183 IVI_Time_Year "IVI_GPS Satellite Time_Year";
CM_ SG_ 1183 IVI_Time_Check "IVI_GPS Satellite Time_Check Sum";
CM_ SG_ 1249 TBOX_SW_VER "TBOX SW Ver., 4 byte ASCII Code";
CM_ SG_ 1249 TBOX_HW_VER "TBOX HW Ver., 4 byte ASCII Code";
CM_ SG_ 1249 ReserveChargeOn_Minute "APP charge request time ON set";
CM_ SG_ 1249 ReserveChargeOn_Hour "APP charge request time ON set";
CM_ SG_ 1249 ReserveChargeOn_Day "APP charge request time ON set";
CM_ SG_ 1249 ReserveChargeOn_Month "APP charge request time ON set";
CM_ SG_ 1249 ReserveChargeOn_Year "APP charge request time ON set";
CM_ SG_ 1249 ReserveChargeOFF_Minute "APP charge request time OFF set";
CM_ SG_ 1249 ReserveChargeOFF_Hour "APP charge request time OFF set";
CM_ SG_ 1249 ReserveChargeOFF_Day "APP charge request time OFF set";
CM_ SG_ 1249 ReserveChargeOFF_Month "APP charge request time OFF set";
CM_ SG_ 1249 ReserveChargeOFF_Year "APP charge request time OFF set";
CM_ SG_ 1249 Charge_Percent_Set "Charge_Percent_Set";
CM_ SG_ 1280 NM_FUSION_ERROR_State "Defined Error states of the CAN Controller";
CM_ SG_ 1280 NM_FUSION_Rpt_Msg_Req "Repeat Message Request";
CM_ SG_ 1280 NM_FUSION_CSB "NM Coordinator Sleep Bit";
CM_ SG_ 1280 NM_FUSION_Active_WU "Active Wakeup Bit";
CM_ SG_ 1280 NM_FUSION_PNI "Partial Network Information Bit (PNI)";
CM_ SG_ 1280 NM_FUSION_Node_ID "Source Node Identifier";
CM_ SG_ 1283 NM_MCU_R_ERROR_State "Defined Error states of the CAN Controller";
CM_ SG_ 1283 NM_MCU_R_Rpt_Msg_Req "Repeat Message Request";
CM_ SG_ 1283 NM_MCU_R_CSB "NM Coordinator Sleep Bit";
CM_ SG_ 1283 NM_MCU_R_Active_WU "Active Wakeup Bit";
CM_ SG_ 1283 NM_MCU_R_PNI "Partial Network Information Bit (PNI)";
CM_ SG_ 1283 NM_MCU_R_Node_ID "Source Node Identifier";
CM_ SG_ 1288 NM_MCU_F_ERROR_State "Defined Error states of the CAN Controller";
CM_ SG_ 1288 NM_MCU_F_Rpt_Msg_Req "Repeat Message Request";
CM_ SG_ 1288 NM_MCU_F_CSB "NM Coordinator Sleep Bit";
CM_ SG_ 1288 NM_MCU_F_Active_WU "Active Wakeup Bit";
CM_ SG_ 1288 NM_MCU_F_PNI "Partial Network Information Bit (PNI)";
CM_ SG_ 1288 NM_MCU_F_Node_ID "Source Node Identifier";
CM_ SG_ 1299 NM_EOP_R_ERROR_State "Defined Error states of the CAN Controller";
CM_ SG_ 1299 NM_EOP_R_Rpt_Msg_Req "Repeat Message Request";
CM_ SG_ 1299 NM_EOP_R_CSB "NM Coordinator Sleep Bit";
CM_ SG_ 1299 NM_EOP_R_Active_WU "Active Wakeup Bit";
CM_ SG_ 1299 NM_EOP_R_PNI "Partial Network Information Bit (PNI)";
CM_ SG_ 1299 NM_EOP_R_Node_ID "Source Node Identifier";
CM_ SG_ 1304 NM_EOP_F_ERROR_State "Defined Error states of the CAN Controller";
CM_ SG_ 1304 NM_EOP_F_Rpt_Msg_Req "Repeat Message Request";
CM_ SG_ 1304 NM_EOP_F_CSB "NM Coordinator Sleep Bit";
CM_ SG_ 1304 NM_EOP_F_Active_WU "Active Wakeup Bit";
CM_ SG_ 1304 NM_EOP_F_PNI "Partial Network Information Bit (PNI)";
CM_ SG_ 1304 NM_EOP_F_Node_ID "Source Node Identifier";
CM_ SG_ 1328 NM_BMS_ERROR_State "Defined Error states of the CAN Controller";
CM_ SG_ 1328 NM_BMS_Rpt_Msg_Req "Repeat Message Request";
CM_ SG_ 1328 NM_BMS_CSB "NM Coordinator Sleep Bit";
CM_ SG_ 1328 NM_BMS_Active_WU "Active Wakeup Bit";
CM_ SG_ 1328 NM_BMS_PNI "Partial Network Information Bit (PNI)";
CM_ SG_ 1328 NM_BMS_Node_ID "Source Node Identifier";
CM_ SG_ 1331 NM_CCU_ERROR_State "Defined Error states of the CAN Controller";
CM_ SG_ 1331 NM_CCU_Rpt_Msg_Req "Repeat Message Request";
CM_ SG_ 1331 NM_CCU_CSB "NM Coordinator Sleep Bit";
CM_ SG_ 1331 NM_CCU_Active_WU "Active Wakeup Bit";
CM_ SG_ 1331 NM_CCU_PNI "Partial Network Information Bit (PNI)";
CM_ SG_ 1331 NM_CCU_Node_ID "Source Node Identifier";
CM_ SG_ 1336 NM_Shifter_ERROR_State "Defined Error states of the CAN Controller";
CM_ SG_ 1336 NM_Shifter_Rpt_Msg_Req "Repeat Message Request";
CM_ SG_ 1336 NM_Shifter_CSB "NM Coordinator Sleep Bit";
CM_ SG_ 1336 NM_Shifter_Active_WU "Active Wakeup Bit";
CM_ SG_ 1336 NM_Shifter_PNI "Partial Network Information Bit (PNI)";
CM_ SG_ 1336 NM_Shifter_Node_ID "Source Node Identifier";
CM_ SG_ 1539 DiagRespFromMCU_R "Diagnostic Response from MCU_R";
CM_ SG_ 1544 DiagRespFromMCU_F "Diagnostic Response from MCU_F";
CM_ SG_ 1555 DiagRespFromEOP_R "Diagnostic Response from EOP_R";
CM_ SG_ 1560 DiagRespFromEOP_F "Diagnostic Response from EOP_F";
CM_ SG_ 1584 DiagRespFromBMS "Diagnostic Response from BMS";
CM_ SG_ 1587 DiagRespFromCCU "Diagnostic Response from CCU";
CM_ SG_ 1592 DiagRespFromShifter "Diagnostic Response from Shifter";
CM_ SG_ 1667 DiagPhysReqToMCU_R "Diagnostic Physical Request to MCU_R";
CM_ SG_ 1672 DiagPhysReqToMCU_F "Diagnostic Physical Request to MCU_F";
CM_ SG_ 1683 DiagPhysReqToEOP_R "Diagnostic Physical Request to EOP_R";
CM_ SG_ 1688 DiagPhysReqToEOP_F "Diagnostic Physical Request to EOP_F";
CM_ SG_ 1712 DiagPhysReqToBMS "Diagnostic Physical Request to BMS";
CM_ SG_ 1715 DiagPhysReqToCCU "Diagnostic Physical Request to CCU";
CM_ SG_ 1720 DiagPhysReqToShifter "Diagnostic Physical Request to Shifter";
CM_ SG_ 2000 DiagFuncReqFT "Diagnostic Functional Request from Tester";
CM_ SG_ 1080 OTA_Up_Backcount "Start Update Backcount";
CM_ SG_ 1080 OTA_DL_Speed "Firmware Package download speed";
CM_ SG_ 1080 OTA_Lock_Req "OTA Lock request to DKC";
CM_ SG_ 1080 OTA_Updating_ECU "Fusion MDA is updating ECU";
CM_ SG_ 1080 OTA_Update_Available "Fusion MDA available for update";
CM_ SG_ 1080 OTA_InVehicle_FW "In Vehicle Firmware Version Status";
CM_ SG_ 1080 OTA_DL_Available "Fusion MDA available for download";
CM_ SG_ 1080 OTA_Mode "Vehicel OTA mode Status";
CM_ SG_ 1080 OTA_Network_Type "Vehicle Network Type";
CM_ SG_ 1080 OTA_MDA_Status "Fusion Master OTA agent status";
CM_ SG_ 1080 OTA_Progress_Rate "MDA download or update progress rate";
CM_ SG_ 1080 OTA_TBOXResetReq "TBOX Reset Request";
CM_ SG_ 552 FWiperAS "Front Wiper Auto Stop";
CM_ SG_ 552 FWiperProtection "Front Wiper Protection";
CM_ SG_ 552 ChargeInletLockSta "Charge Inlet lock signal status";
CM_ SG_ 552 FLTurnLampC "Front Left TurnLamp Current";
CM_ SG_ 552 FRTurnLampC "Front Right TurnLamp Current";
CM_ SG_ 552 AGS_Actuator_Blocked "Feedback of Shutter blocked";
CM_ SG_ 552 AGS_Actuator_Fault "Feedback of Shutter actuator fault";
CM_ SG_ 552 AGS_Calibration_Active "Feedback of  Shutter calibration active";
CM_ SG_ 552 AGS_Calibration_Indicated "Feedback of Shutter calibration indicated";
CM_ SG_ 552 AGS_Electrical_Error "Feedback of electrical error";
CM_ SG_ 552 AGS_Sensor_Error "Feedback of Shutter position sensor fault";
CM_ SG_ 552 AGS_Temperature_Error "Feedback for overtemprature error";
CM_ SG_ 552 AGS_Low_Voltage_Error "Feedback for over/under voltage error";
CM_ SG_ 552 AGS_Actual_Position "Position feedback from the actuator";
CM_ SG_ 552 AGS_LINResponse_Error "Feedback of Response error bit";
CM_ SG_ 552 AGS_Calibration_Enabled "Command for start calibration sequence (rising edge)";
CM_ SG_ 552 AGS_Position_Request "AGS Position Request from Zone FR to AGS";
CM_ SG_ 496 SysPwrSta "System power mode";
CM_ SG_ 496 PowerUpState "Power up mode";
CM_ SG_ 496 PowerUpFault "Power up fault";
CM_ SG_ 496 PowerDownState "Power down state";
CM_ SG_ 496 PowerDownFault "Power down fault";
CM_ SG_ 496 PwrStaSelect "Power state select";
CM_ SG_ 496 PwrStaConstraint "Power state constraint";
CM_ SG_ 496 TCountSta "Timmer counting state";
CM_ SG_ 496 PwrUpReq "Power up request";
CM_ SG_ 496 Rr_TqSource "Rear EDU Torque Source";
CM_ SG_ 496 Fr_TqSource "Front EDU Torque Source";
CM_ SG_ 496 LVBattVoltSta "LV battery voltage state";
CM_ SG_ 496 HVTHCMSysAvail "HV THCM syetem avaliable state";
CM_ SG_ 496 VehHVPwrAvail4THCM "Vehicle HV power avalible for THCM";
CM_ SG_ 496 VCUBrkSWSta "VCU brake SW state";
CM_ SG_ 496 VCUFLDoorSta "VCU FL door state";
CM_ SG_ 496 VCUFRDoorSta "VCU FR door state";
CM_ SG_ 496 VCURLDoorSta "VCU RL door state";
CM_ SG_ 496 VCURRDoorSta "VCU RR door state";
CM_ SG_ 496 SysAllowReadySta "System allow  to ready state";
CM_ SG_ 496 HVRlyOpFail "HV relay opend fail";
CM_ SG_ 496 MCUActDisFail "MCU active discharge fail";
CM_ SG_ 496 PwrStaONTOIVIPopReq "Power state ON timeout IVI popup";
CM_ SG_ 496 PwrStaTOSta "Power state timeout state";
CM_ SG_ 496 PwrStaONTOIVIPopT "Count down time value for power state ON timeout IVI popup";
CM_ SG_ 496 SchedChgTOSta "Schedule charge timeout state";
CM_ SG_ 496 SilentChkAllowSleep "Silent charge check allow sleep flag.";
CM_ SG_ 496 LVSilentChrgSta "V Silent Chrge State";
CM_ SG_ 496 LVSilentChrgLv "LV silent charging level";
CM_ SG_ 496 LVSilentChrgReq "LV Silent Chrge Request";
CM_ SG_ 496 TimerAllowSleep "Timer allow sleep flag.";
CM_ SG_ 496 PMMAllowECUSleep "PMM allow ECU sleep flag.";
CM_ SG_ 496 LVChrgHoldTAct "Calibration value for LV charge hold time";
CM_ SG_ 496 LVBattChrgtimeAct "V Battery charge time.";
CM_ SG_ 496 EVCCAplusPwrUpReq "EVCC A-plus signal power up request.";
CM_ SG_ 496 FDADC12VDetAvg "FD ADC 12V detect voltage average value";
CM_ SG_ 496 FDC_VMC_ActStESCYaw_Sta "Actual standard ESC yaw rate";
CM_ SG_ 496 FDC_VMC_LongAcc_Sta "longitudinal acceleration";
CM_ SG_ 496 FDC_VCU_VehActSpd_Sta "Actual max slide rate";
CM_ SG_ 496 FDC_VCU_ActMaxSlideRate_Sta "Actual max slide rate";
CM_ SG_ 496 FDC_VCU_SlideRegenLimTq_Sta "Slide regen limit tq";
CM_ SG_ 496 FDADC12VDet "FD ADC 12V detect voltage value";
CM_ SG_ 496 FDC_VCU_DTCCarousel_Sta "DTC carousel";
CM_ SG_ 496 FDC_VCU_VehMalfunLevel_Sta "Vehicle malfunction level";
CM_ SG_ 496 FDC_VCU_RWDRDCActive_Sta "RWD RDC active";
CM_ SG_ 496 FDC_VCU_AllowMovThd_OTA_Sta "OTA allow move threshold";
CM_ SG_ 496 FDC_VCU_PwrReq_OTA_Sta "Power request by OTA";
CM_ SG_ 496 FDC_VCU_RegenTqLimitEn_Sta "Regen torque limit enable";
CM_ SG_ 496 FDC_VCU_ForceP_Cmd "Force P gear command";
CM_ SG_ 496 FDC_VMC_AntiSpdLimEn_Sta "Anti speed limit enable";
BA_DEF_ BO_ "GenMsgSendType" ENUM "Cycle","NoMsgSendType","IfActive","Event","CA","CE";
BA_DEF_ BO_ "GenMsgNrOfRepetition" INT 0 0;
BA_DEF_ BO_ "GenMsgILSupport" ENUM "No","Yes";
BA_DEF_ BO_ "GenMsgDelayTime" INT 0 0;
BA_DEF_ BO_ "GenMsgCycleTimeFast" INT 0 0;
BA_DEF_ BO_ "GenMsgCycleTime" INT 0 0;
BA_DEF_ BO_ "DiagResponse" ENUM "No","Yes";
BA_DEF_ BO_ "DiagRequest" ENUM "No","Yes";
BA_DEF_ BO_ "NmMessage" ENUM "No","Yes";
BA_DEF_ BO_ "VFrameFormat" ENUM "StandardCAN","ExtendedCAN","reserved","reserved","reserved","reserved","reserved","reserved","reserved","reserved","reserved","reserved","reserved","reserved","StandardCAN_FD","ExtendedCAN_FD";
BA_DEF_ BO_ "GenMsgRequestable" INT 0 1;
BA_DEF_ BO_ "DataID_Hex" HEX 0 65535;
BA_DEF_ BO_ "DoIPLogicalAddress" STRING ;
BA_DEF_ BO_ "DataID" STRING ;
BA_DEF_ BO_ "CANFD_BRS" ENUM "0","1";
BA_DEF_ SG_ "GenSigInvalidValue" HEX 0 0;
BA_DEF_ SG_ "GenSigStartValue" HEX 0 0;
BA_DEF_ SG_ "GenSigInactiveValue" HEX 0 0;
BA_DEF_ SG_ "GenSigRoutingTimeoutValue_String" STRING ;
BA_DEF_ SG_ "GenSigRoutingTimeoutValue" HEX 0 0;
BA_DEF_ SG_ "GenSigSendType" ENUM "Cycle","OnWrite","OnWriteWithRepetition","OnChange","OnChangeWithRepetition","IfActive","IfActiveWithRepetition","NoSigSendType","vector_leerstring";
BA_DEF_ SG_ "SigType" ENUM "Default","Range","RangeSigned","ASCII","Discrete","Control","ReferencePGN","DTC","StringDelimiter","StringLength","StringLengthControl","MessageCounter","MessageChecksum";
BA_DEF_ SG_ "GenSigILSupport" ENUM "No","Yes";
BA_DEF_DEF_ "GenMsgSendType" "Cycle";
BA_DEF_DEF_ "GenMsgNrOfRepetition" 0;
BA_DEF_DEF_ "GenMsgILSupport" "Yes";
BA_DEF_DEF_ "GenMsgDelayTime" 0;
BA_DEF_DEF_ "GenMsgCycleTimeFast" 0;
BA_DEF_DEF_ "GenMsgCycleTime" 100;
BA_DEF_DEF_ "DiagResponse" "No";
BA_DEF_DEF_ "DiagRequest" "No";
BA_DEF_DEF_ "NmMessage" "No";
BA_DEF_DEF_ "VFrameFormat" "StandardCAN";
BA_DEF_DEF_ "GenMsgRequestable" 1;
BA_DEF_DEF_ "DataID_Hex" 0;
BA_DEF_DEF_ "DoIPLogicalAddress" "";
BA_DEF_DEF_ "DataID" "";
BA_DEF_DEF_ "CANFD_BRS" "1";
BA_DEF_DEF_ "GenSigInvalidValue" 0;
BA_DEF_DEF_ "GenSigStartValue" 0;
BA_DEF_DEF_ "GenSigInactiveValue" 0;
BA_DEF_DEF_ "GenSigRoutingTimeoutValue_String" "";
BA_DEF_DEF_ "GenSigRoutingTimeoutValue" 0;
BA_DEF_DEF_ "GenSigSendType" "Cycle";
BA_DEF_DEF_ "SigType" "Default";
BA_DEF_DEF_ "GenSigILSupport" "Yes";
BA_ "GenMsgNrOfRepetition" BO_ 1173 1;
BA_ "GenMsgCycleTime" BO_ 1173 200;
BA_ "GenMsgDelayTime" BO_ 1173 5;
BA_ "GenMsgCycleTimeFast" BO_ 1173 20;
BA_ "GenMsgSendType" BO_ 1173 5;
BA_ "VFrameFormat" BO_ 1173 14;
BA_ "GenMsgCycleTime" BO_ 1183 1000;
BA_ "VFrameFormat" BO_ 1183 14;
BA_ "GenMsgNrOfRepetition" BO_ 1249 1;
BA_ "GenMsgCycleTime" BO_ 1249 1000;
BA_ "GenMsgCycleTimeFast" BO_ 1249 10;
BA_ "GenMsgSendType" BO_ 1249 5;
BA_ "VFrameFormat" BO_ 1249 14;
BA_ "GenMsgCycleTime" BO_ 1280 0;
BA_ "NmMessage" BO_ 1280 1;
BA_ "GenMsgSendType" BO_ 1280 3;
BA_ "GenMsgCycleTime" BO_ 1283 0;
BA_ "NmMessage" BO_ 1283 1;
BA_ "GenMsgSendType" BO_ 1283 3;
BA_ "GenMsgCycleTime" BO_ 1288 0;
BA_ "NmMessage" BO_ 1288 1;
BA_ "GenMsgSendType" BO_ 1288 3;
BA_ "GenMsgCycleTime" BO_ 1299 0;
BA_ "NmMessage" BO_ 1299 1;
BA_ "GenMsgSendType" BO_ 1299 3;
BA_ "GenMsgCycleTime" BO_ 1304 0;
BA_ "NmMessage" BO_ 1304 1;
BA_ "GenMsgSendType" BO_ 1304 3;
BA_ "GenMsgCycleTime" BO_ 1328 0;
BA_ "NmMessage" BO_ 1328 1;
BA_ "GenMsgSendType" BO_ 1328 3;
BA_ "GenMsgCycleTime" BO_ 1331 0;
BA_ "NmMessage" BO_ 1331 1;
BA_ "GenMsgSendType" BO_ 1331 3;
BA_ "GenMsgCycleTime" BO_ 1336 0;
BA_ "NmMessage" BO_ 1336 1;
BA_ "GenMsgSendType" BO_ 1336 3;
BA_ "GenMsgCycleTime" BO_ 1539 0;
BA_ "DiagResponse" BO_ 1539 1;
BA_ "GenMsgSendType" BO_ 1539 3;
BA_ "VFrameFormat" BO_ 1539 14;
BA_ "DoIPLogicalAddress" BO_ 1539 "0x0683";
BA_ "GenMsgCycleTime" BO_ 1544 0;
BA_ "DiagResponse" BO_ 1544 1;
BA_ "GenMsgSendType" BO_ 1544 3;
BA_ "VFrameFormat" BO_ 1544 14;
BA_ "DoIPLogicalAddress" BO_ 1544 "0x0688";
BA_ "GenMsgCycleTime" BO_ 1555 0;
BA_ "DiagResponse" BO_ 1555 1;
BA_ "GenMsgSendType" BO_ 1555 3;
BA_ "VFrameFormat" BO_ 1555 14;
BA_ "DoIPLogicalAddress" BO_ 1555 "0x0693";
BA_ "GenMsgCycleTime" BO_ 1560 0;
BA_ "DiagResponse" BO_ 1560 1;
BA_ "GenMsgSendType" BO_ 1560 3;
BA_ "VFrameFormat" BO_ 1560 14;
BA_ "DoIPLogicalAddress" BO_ 1560 "0x0698";
BA_ "GenMsgCycleTime" BO_ 1584 0;
BA_ "DiagResponse" BO_ 1584 1;
BA_ "GenMsgSendType" BO_ 1584 3;
BA_ "VFrameFormat" BO_ 1584 14;
BA_ "DoIPLogicalAddress" BO_ 1584 "0x06B0";
BA_ "GenMsgCycleTime" BO_ 1587 0;
BA_ "DiagResponse" BO_ 1587 1;
BA_ "GenMsgSendType" BO_ 1587 3;
BA_ "VFrameFormat" BO_ 1587 14;
BA_ "DoIPLogicalAddress" BO_ 1587 "0x06B3";
BA_ "GenMsgCycleTime" BO_ 1592 0;
BA_ "DiagResponse" BO_ 1592 1;
BA_ "GenMsgSendType" BO_ 1592 3;
BA_ "VFrameFormat" BO_ 1592 14;
BA_ "DoIPLogicalAddress" BO_ 1592 "0x06B8";
BA_ "GenMsgCycleTime" BO_ 1667 0;
BA_ "DiagRequest" BO_ 1667 1;
BA_ "GenMsgSendType" BO_ 1667 3;
BA_ "VFrameFormat" BO_ 1667 14;
BA_ "DoIPLogicalAddress" BO_ 1667 "0x0683";
BA_ "GenMsgCycleTime" BO_ 1672 0;
BA_ "DiagRequest" BO_ 1672 1;
BA_ "GenMsgSendType" BO_ 1672 3;
BA_ "VFrameFormat" BO_ 1672 14;
BA_ "DoIPLogicalAddress" BO_ 1672 "0x0688";
BA_ "GenMsgCycleTime" BO_ 1683 0;
BA_ "DiagRequest" BO_ 1683 1;
BA_ "GenMsgSendType" BO_ 1683 3;
BA_ "VFrameFormat" BO_ 1683 14;
BA_ "DoIPLogicalAddress" BO_ 1683 "0x0693";
BA_ "GenMsgCycleTime" BO_ 1688 0;
BA_ "DiagRequest" BO_ 1688 1;
BA_ "GenMsgSendType" BO_ 1688 3;
BA_ "VFrameFormat" BO_ 1688 14;
BA_ "DoIPLogicalAddress" BO_ 1688 "0x0698";
BA_ "GenMsgCycleTime" BO_ 1712 0;
BA_ "DiagRequest" BO_ 1712 1;
BA_ "GenMsgSendType" BO_ 1712 3;
BA_ "VFrameFormat" BO_ 1712 14;
BA_ "DoIPLogicalAddress" BO_ 1712 "0x06B0";
BA_ "GenMsgCycleTime" BO_ 1715 0;
BA_ "DiagRequest" BO_ 1715 1;
BA_ "GenMsgSendType" BO_ 1715 3;
BA_ "VFrameFormat" BO_ 1715 14;
BA_ "DoIPLogicalAddress" BO_ 1715 "0x06B3";
BA_ "GenMsgCycleTime" BO_ 1720 0;
BA_ "DiagRequest" BO_ 1720 1;
BA_ "GenMsgSendType" BO_ 1720 3;
BA_ "VFrameFormat" BO_ 1720 14;
BA_ "DoIPLogicalAddress" BO_ 1720 "0x06B8";
BA_ "GenMsgCycleTime" BO_ 2000 0;
BA_ "DiagRequest" BO_ 2000 1;
BA_ "GenMsgSendType" BO_ 2000 3;
BA_ "VFrameFormat" BO_ 2000 14;
BA_ "DoIPLogicalAddress" BO_ 2000 "0xEFFF";
BA_ "GenMsgNrOfRepetition" BO_ 1080 1;
BA_ "GenMsgCycleTime" BO_ 1080 200;
BA_ "GenMsgCycleTimeFast" BO_ 1080 20;
BA_ "GenMsgSendType" BO_ 1080 5;
BA_ "VFrameFormat" BO_ 1080 14;
BA_ "GenMsgNrOfRepetition" BO_ 552 1;
BA_ "GenMsgCycleTime" BO_ 552 200;
BA_ "GenMsgCycleTimeFast" BO_ 552 50;
BA_ "GenMsgSendType" BO_ 552 5;
BA_ "VFrameFormat" BO_ 552 14;
BA_ "GenMsgNrOfRepetition" BO_ 496 1;
BA_ "GenMsgCycleTime" BO_ 496 10;
BA_ "GenMsgCycleTimeFast" BO_ 496 2;
BA_ "VFrameFormat" BO_ 496 14;
BA_ "GenSigSendType" SG_ 1173 AVM_parking_cancel 3;
BA_ "GenSigSendType" SG_ 1173 AVM_parking_excute 3;
BA_ "GenSigSendType" SG_ 1173 AVM_OFF_Rec_Butt 3;
BA_ "GenSigInvalidValue" SG_ 1173 IVI_AGSCloseSW 2;
BA_ "GenSigSendType" SG_ 1173 IVI_AGSCloseSW 3;
BA_ "GenSigInvalidValue" SG_ 1173 IVI_LVChrgFuncSW 2;
BA_ "GenSigSendType" SG_ 1173 IVI_LVChrgFuncSW 3;
BA_ "GenSigInvalidValue" SG_ 1173 IVI_PwrLockSW 2;
BA_ "GenSigSendType" SG_ 1173 IVI_PwrLockSW 3;
BA_ "GenSigInvalidValue" SG_ 1173 IVI_CoastDwSW 2;
BA_ "GenSigSendType" SG_ 1173 IVI_CoastDwSW 3;
BA_ "GenSigInvalidValue" SG_ 1173 IVI_ActvDmpDisabSW 2;
BA_ "GenSigSendType" SG_ 1173 IVI_ActvDmpDisabSW 3;
BA_ "GenSigInvalidValue" SG_ 1173 Roll_Mode_SW_Cmd 3;
BA_ "GenSigSendType" SG_ 1173 Roll_Mode_SW_Cmd 3;
BA_ "GenSigInvalidValue" SG_ 1173 TCS_SW_Cmd 3;
BA_ "GenSigSendType" SG_ 1173 TCS_SW_Cmd 3;
BA_ "GenSigInvalidValue" SG_ 1173 SLIF_BUTT 3;
BA_ "GenSigSendType" SG_ 1173 SLIF_BUTT 3;
BA_ "GenSigSendType" SG_ 1173 Roll_Eng_Mode 3;
BA_ "GenSigInvalidValue" SG_ 1173 SOC_Limit_Set 31;
BA_ "GenSigStartValue" SG_ 1173 SOC_Limit_Set 25;
BA_ "GenSigSendType" SG_ 1173 CDL_Lock_Butt 3;
BA_ "GenSigSendType" SG_ 1173 CDL_Unlock_Butt 3;
BA_ "GenSigSendType" SG_ 1173 SOC_ADJ_BUTT 3;
BA_ "GenSigSendType" SG_ 1173 AC_Chg_Cur_Set 3;
BA_ "GenSigInvalidValue" SG_ 1173 IVI_ISA_OffsetSpd 15;
BA_ "GenSigSendType" SG_ 1173 IVI_RR_Def_Req 3;
BA_ "GenSigInvalidValue" SG_ 1173 CAAS_Sw 2;
BA_ "GenSigSendType" SG_ 1173 CAAS_Sw 3;
BA_ "GenSigSendType" SG_ 1173 IVI_PTG_Mode_SW 3;
BA_ "GenSigSendType" SG_ 1173 IVI_PTG_Sta_SW 3;
BA_ "GenSigInvalidValue" SG_ 1173 MFRD_N_Bright_Req 127;
BA_ "GenSigSendType" SG_ 1173 MFRD_N_Bright_Req 3;
BA_ "GenSigSendType" SG_ 1173 HeadLampSW 3;
BA_ "GenSigInvalidValue" SG_ 1173 OFF_AC_MODE 7;
BA_ "GenSigSendType" SG_ 1173 OFF_AC_MODE 3;
BA_ "GenSigSendType" SG_ 1173 TurnSwTimeSet 3;
BA_ "GenSigSendType" SG_ 1173 ESC_SW_Cmd 3;
BA_ "GenSigSendType" SG_ 1173 sigHvacRearReq 3;
BA_ "GenSigStartValue" SG_ 1173 sigWindDirZon3Req 7;
BA_ "GenSigSendType" SG_ 1173 sigWindDirZon3Req 3;
BA_ "GenSigSendType" SG_ 1173 sigAirIntenZon3Req 3;
BA_ "GenSigSendType" SG_ 1173 sigAirIntenZon1Req 3;
BA_ "GenSigSendType" SG_ 1173 sigSetTempZon3Req 3;
BA_ "GenSigSendType" SG_ 1173 sigSetTempZon2Req 3;
BA_ "GenSigSendType" SG_ 1173 sigRecircReq 3;
BA_ "GenSigSendType" SG_ 1173 sigHvacReq 3;
BA_ "GenSigSendType" SG_ 1173 sigSetTempZon1Req 3;
BA_ "GenSigSendType" SG_ 1173 sigHvacFrontReq 3;
BA_ "GenSigSendType" SG_ 1173 sigDfrstReq 3;
BA_ "GenSigStartValue" SG_ 1173 L_Drv_ControlCommand 127;
BA_ "GenSigRoutingTimeoutValue" SG_ 1173 L_Drv_ControlCommand 127;
BA_ "GenSigStartValue" SG_ 1173 L_Pas_ControlCommand 127;
BA_ "GenSigRoutingTimeoutValue" SG_ 1173 L_Pas_ControlCommand 127;
BA_ "GenSigStartValue" SG_ 1173 L_RLD_ControlCommand 127;
BA_ "GenSigRoutingTimeoutValue" SG_ 1173 L_RLD_ControlCommand 127;
BA_ "GenSigStartValue" SG_ 1173 L_RRD_ControlCommand 127;
BA_ "GenSigRoutingTimeoutValue" SG_ 1173 L_RRD_ControlCommand 127;
BA_ "GenSigInvalidValue" SG_ 1173 METER_Malfunc_Sta 3;
BA_ "GenSigSendType" SG_ 1173 sigFootReq 3;
BA_ "GenSigSendType" SG_ 1173 sigFaceReq 3;
BA_ "GenSigSendType" SG_ 1173 Sched_Chg_Start 3;
BA_ "GenSigSendType" SG_ 1173 Sched_Chg_wake 3;
BA_ "GenSigSendType" SG_ 1173 Sched_Chg_Stop 3;
BA_ "GenSigInvalidValue" SG_ 1173 Sched_Chg_limit 31;
BA_ "GenSigStartValue" SG_ 1173 Sched_Chg_limit 25;
BA_ "GenSigStartValue" SG_ 1173 Walkaway_Lock_SW 1;
BA_ "GenSigSendType" SG_ 1173 Walkaway_Lock_SW 3;
BA_ "GenSigStartValue" SG_ 1173 Approach_Unlock_SW 1;
BA_ "GenSigSendType" SG_ 1173 Approach_Unlock_SW 3;
BA_ "GenSigStartValue" SG_ 1173 FalseNPrevent_SW 1;
BA_ "GenSigSendType" SG_ 1173 IVI_CreepSW_Req 3;
BA_ "GenSigSendType" SG_ 1173 IVI_PTG_Open_Height 3;
BA_ "GenSigInvalidValue" SG_ 1173 SOC_V2LLimit 15;
BA_ "GenSigInvalidValue" SG_ 1249 Charge_Percent_Set 101;
BA_ "GenSigStartValue" SG_ 1249 Charge_Percent_Set 100;
BA_ "GenSigSendType" SG_ 1249 Charge_Percent_Set 3;
BA_ "GenSigSendType" SG_ 1280 NM_FUSION_ERROR_State 7;
BA_ "GenSigSendType" SG_ 1280 NM_FUSION_Rpt_Msg_Req 7;
BA_ "GenSigSendType" SG_ 1280 NM_FUSION_CSB 7;
BA_ "GenSigSendType" SG_ 1280 NM_FUSION_Active_WU 7;
BA_ "GenSigSendType" SG_ 1280 NM_FUSION_PNI 7;
BA_ "GenSigSendType" SG_ 1280 NM_FUSION_Node_ID 7;
BA_ "GenSigSendType" SG_ 1283 NM_MCU_R_ERROR_State 7;
BA_ "GenSigSendType" SG_ 1283 NM_MCU_R_Rpt_Msg_Req 7;
BA_ "GenSigSendType" SG_ 1283 NM_MCU_R_CSB 7;
BA_ "GenSigSendType" SG_ 1283 NM_MCU_R_Active_WU 7;
BA_ "GenSigSendType" SG_ 1283 NM_MCU_R_PNI 7;
BA_ "GenSigSendType" SG_ 1283 NM_MCU_R_Node_ID 7;
BA_ "GenSigSendType" SG_ 1288 NM_MCU_F_ERROR_State 7;
BA_ "GenSigSendType" SG_ 1288 NM_MCU_F_Rpt_Msg_Req 7;
BA_ "GenSigSendType" SG_ 1288 NM_MCU_F_CSB 7;
BA_ "GenSigSendType" SG_ 1288 NM_MCU_F_Active_WU 7;
BA_ "GenSigSendType" SG_ 1288 NM_MCU_F_PNI 7;
BA_ "GenSigSendType" SG_ 1288 NM_MCU_F_Node_ID 7;
BA_ "GenSigSendType" SG_ 1299 NM_EOP_R_ERROR_State 7;
BA_ "GenSigSendType" SG_ 1299 NM_EOP_R_Rpt_Msg_Req 7;
BA_ "GenSigSendType" SG_ 1299 NM_EOP_R_CSB 7;
BA_ "GenSigSendType" SG_ 1299 NM_EOP_R_Active_WU 7;
BA_ "GenSigSendType" SG_ 1299 NM_EOP_R_PNI 7;
BA_ "GenSigSendType" SG_ 1299 NM_EOP_R_Node_ID 7;
BA_ "GenSigSendType" SG_ 1304 NM_EOP_F_ERROR_State 7;
BA_ "GenSigSendType" SG_ 1304 NM_EOP_F_Rpt_Msg_Req 7;
BA_ "GenSigSendType" SG_ 1304 NM_EOP_F_CSB 7;
BA_ "GenSigSendType" SG_ 1304 NM_EOP_F_Active_WU 7;
BA_ "GenSigSendType" SG_ 1304 NM_EOP_F_PNI 7;
BA_ "GenSigSendType" SG_ 1304 NM_EOP_F_Node_ID 7;
BA_ "GenSigSendType" SG_ 1328 NM_BMS_ERROR_State 7;
BA_ "GenSigSendType" SG_ 1328 NM_BMS_Rpt_Msg_Req 7;
BA_ "GenSigSendType" SG_ 1328 NM_BMS_CSB 7;
BA_ "GenSigSendType" SG_ 1328 NM_BMS_Active_WU 7;
BA_ "GenSigSendType" SG_ 1328 NM_BMS_PNI 7;
BA_ "GenSigSendType" SG_ 1328 NM_BMS_Node_ID 7;
BA_ "GenSigSendType" SG_ 1331 NM_CCU_ERROR_State 7;
BA_ "GenSigSendType" SG_ 1331 NM_CCU_Rpt_Msg_Req 7;
BA_ "GenSigSendType" SG_ 1331 NM_CCU_CSB 7;
BA_ "GenSigSendType" SG_ 1331 NM_CCU_Active_WU 7;
BA_ "GenSigSendType" SG_ 1331 NM_CCU_PNI 7;
BA_ "GenSigSendType" SG_ 1331 NM_CCU_Node_ID 7;
BA_ "GenSigSendType" SG_ 1336 NM_Shifter_ERROR_State 7;
BA_ "GenSigSendType" SG_ 1336 NM_Shifter_Rpt_Msg_Req 7;
BA_ "GenSigSendType" SG_ 1336 NM_Shifter_CSB 7;
BA_ "GenSigSendType" SG_ 1336 NM_Shifter_Active_WU 7;
BA_ "GenSigSendType" SG_ 1336 NM_Shifter_PNI 7;
BA_ "GenSigSendType" SG_ 1336 NM_Shifter_Node_ID 7;
BA_ "GenSigSendType" SG_ 1539 DiagRespFromMCU_R 3;
BA_ "GenSigSendType" SG_ 1544 DiagRespFromMCU_F 3;
BA_ "GenSigSendType" SG_ 1555 DiagRespFromEOP_R 3;
BA_ "GenSigSendType" SG_ 1560 DiagRespFromEOP_F 3;
BA_ "GenSigSendType" SG_ 1584 DiagRespFromBMS 3;
BA_ "GenSigSendType" SG_ 1587 DiagRespFromCCU 3;
BA_ "GenSigSendType" SG_ 1592 DiagRespFromShifter 3;
BA_ "GenSigSendType" SG_ 1667 DiagPhysReqToMCU_R 3;
BA_ "GenSigSendType" SG_ 1672 DiagPhysReqToMCU_F 3;
BA_ "GenSigSendType" SG_ 1683 DiagPhysReqToEOP_R 3;
BA_ "GenSigSendType" SG_ 1688 DiagPhysReqToEOP_F 3;
BA_ "GenSigSendType" SG_ 1712 DiagPhysReqToBMS 3;
BA_ "GenSigSendType" SG_ 1715 DiagPhysReqToCCU 3;
BA_ "GenSigSendType" SG_ 1720 DiagPhysReqToShifter 3;
BA_ "GenSigSendType" SG_ 2000 DiagFuncReqFT 3;
BA_ "GenSigInvalidValue" SG_ 1080 OTA_Up_Backcount 122;
BA_ "GenSigSendType" SG_ 1080 OTA_Up_Backcount 3;
BA_ "GenSigSendType" SG_ 1080 OTA_DL_Speed 3;
BA_ "GenSigSendType" SG_ 1080 OTA_Lock_Req 3;
BA_ "GenSigInvalidValue" SG_ 1080 OTA_Updating_ECU 30;
BA_ "GenSigSendType" SG_ 1080 OTA_Updating_ECU 3;
BA_ "GenSigSendType" SG_ 1080 OTA_Update_Available 3;
BA_ "GenSigSendType" SG_ 1080 OTA_InVehicle_FW 3;
BA_ "GenSigSendType" SG_ 1080 OTA_DL_Available 3;
BA_ "GenSigSendType" SG_ 1080 OTA_Mode 3;
BA_ "GenSigSendType" SG_ 1080 OTA_Network_Type 3;
BA_ "GenSigSendType" SG_ 1080 OTA_MDA_Status 3;
BA_ "GenSigInvalidValue" SG_ 1080 OTA_Progress_Rate 102;
BA_ "GenSigSendType" SG_ 1080 OTA_Progress_Rate 3;
BA_ "GenSigInvalidValue" SG_ 552 EWP1_RPM_Target_EWP_Rq 255;
BA_ "GenSigInvalidValue" SG_ 552 EWP3_RPM_Target_EWP_Rq 255;
BA_ "GenSigInvalidValue" SG_ 552 EWP2_RPM_Target_EWP_Rq 255;
BA_ "GenSigSendType" SG_ 552 FWiperAS 3;
BA_ "GenSigSendType" SG_ 552 FWiperProtection 3;
BA_ "GenSigSendType" SG_ 552 FLTurnLampC 3;
BA_ "GenSigSendType" SG_ 552 FRTurnLampC 3;
BA_ "GenSigStartValue" SG_ 552 AGS_Actual_Position 127;
BA_ "GenSigStartValue" SG_ 496 FDC_VMC_ActStESCYaw_Sta 30000;
BA_ "GenSigInactiveValue" SG_ 496 FDC_VMC_ActStESCYaw_Sta 30000;
BA_ "GenSigStartValue" SG_ 496 FDC_VMC_LongAcc_Sta 20000;
BA_ "GenSigInactiveValue" SG_ 496 FDC_VMC_LongAcc_Sta 20000;
BA_ "GenSigStartValue" SG_ 496 FDC_VCU_VehActSpd_Sta 30000;
BA_ "GenSigInactiveValue" SG_ 496 FDC_VCU_VehActSpd_Sta 30000;
BA_ "GenSigStartValue" SG_ 496 FDC_VCU_ActMaxSlideRate_Sta 15000;
BA_ "GenSigInactiveValue" SG_ 496 FDC_VCU_ActMaxSlideRate_Sta 15000;
BA_ "GenSigStartValue" SG_ 496 FDC_VCU_SlideRegenLimTq_Sta 10600;
BA_ "GenSigInactiveValue" SG_ 496 FDC_VCU_SlideRegenLimTq_Sta 10600;
BA_ "GenSigInvalidValue" SG_ 496 FDC_VCU_VehMalfunLevel_Sta 5;
BA_ "GenSigRoutingTimeoutValue_String" SG_ 496 FDC_VCU_VehMalfunLevel_Sta "0x5";
BA_ "GenSigInvalidValue" SG_ 496 FDC_VCU_AllowMovThd_OTA_Sta 2;
BA_ "GenSigRoutingTimeoutValue_String" SG_ 496 FDC_VCU_AllowMovThd_OTA_Sta "0x2";
VAL_ 1173 AVM_parking_cancel 2 "invalid" 1 "press" 0 "release";
VAL_ 1173 AVM_parking_excute 3 "remote request" 2 "invalid" 1 "press" 0 "release";
VAL_ 1173 AVM_OFF_Rec_Butt 1 "ON" 0 "OFF";
VAL_ 1173 IVI_AGSCloseSW 3 "Undefined" 2 "Invalid" 1 "Press (>0.5s)" 0 "Release";
VAL_ 1173 IVI_LVChrgFuncSW 3 "Undefined" 2 "Invalid" 1 "Press (>0.5s)" 0 "Release";
VAL_ 1173 IVI_PwrLockSW 3 "Undefined" 2 "Invalid" 1 "Press (>0.5s)" 0 "Release";
VAL_ 1173 IVI_CoastDwSW 3 "Undefined" 2 "Invalid" 1 "Press (>0.5s)" 0 "Release";
VAL_ 1173 IVI_ActvDmpDisabSW 3 "Undefined" 2 "Invalid" 1 "Press (>0.5s)" 0 "Release";
VAL_ 1173 Roll_Mode_SW_Cmd 3 "Invaild" 2 "Undefined" 1 "Press" 0 "Release";
VAL_ 1173 TCS_SW_Cmd 3 "Invaild" 2 "Undefined" 1 "Press" 0 "Release";
VAL_ 1173 SLIF_BUTT 2 "Invalid" 1 "Pressed" 0 "No request";
VAL_ 1173 Roll_Eng_Mode 1 "on" 0 "off";
VAL_ 1173 SOC_Limit_Set 31 "invalid" 26 "~0x1E undefined" 0 "~0x19 50%~100%";
VAL_ 1173 CDL_Lock_Butt 1 "Press" 0 "Release";
VAL_ 1173 CDL_Unlock_Butt 1 "Press" 0 "Release";
VAL_ 1173 SOC_ADJ_BUTT 1 "Press" 0 "Release";
VAL_ 1173 IVI_ISA_OffsetSpd 15 "Invalid" 14 "reserve" 13 "reserve" 12 "reserve" 11 "5 mph" 10 "0 mph" 9 "-5 mph" 8 "reserve" 7 "reserve" 6 "reserve" 5 "+10 km/h" 4 "+5 km/h" 3 "0 km/h" 2 "-5 km/h" 1 "-10 km/h" 0 "Off";
VAL_ 1173 RoomLampMode 1 "OFF Mode" 0 "DoorMode";
VAL_ 1173 NAVI_SpeedLimit 31 "80mph" 30 "75mph" 29 "70mph" 28 "65mph" 27 "60mph" 26 "55mph" 25 "50mph" 24 "45mph" 23 "40mph" 22 "35mph" 21 "30mph" 20 "25mph" 19 "20mph" 18 "15mph" 17 "10mph" 16 "160 km/h" 15 "150 km/h" 14 "140 km/h" 13 "130 km/h" 12 "120 km/h" 11 "110 km/h" 10 "100 km/h" 9 "90 km/h" 8 "80 km/h" 7 "70 km/h" 6 "60 km/h" 5 "50 km/h" 4 "40 km/h" 3 "30 km/h" 2 "20 km/h" 1 "10 km/h" 0 "No request";
VAL_ 1173 NAVI_RoadClass 7 "undefined" 6 "undefined" 5 "Freeway" 4 "School" 3 "Street" 2 "Interurban" 1 "City" 0 "NA";
VAL_ 1173 NAVI_LinkClass 15 "undefined" 14 "undefined" 13 "undefined" 12 "undefined" 11 "undefined" 10 "undefined" 9 "undefined" 8 "etc" 7 "shoulder" 6 "ramp" 5 "Freeway" 4 "Bus lane" 3 "Roundabout" 2 "City Lv2" 1 "City Lv1" 0 "NA";
VAL_ 1173 NAVI_ForwardLinkLevel 15 "undefined" 14 "undefined" 13 "undefined" 12 "undefined" 11 "undefined" 10 "undefined" 9 "undefined" 8 "etc" 7 "shoulder" 6 "ramp" 5 "Freeway" 4 "Bus lane" 3 "Roundabout" 2 "City Lv2" 1 "City Lv1" 0 "NA";
VAL_ 1173 SenstivityPosition 15 "not used" 14 "not used" 13 "not used" 12 "not used" 11 "not used" 10 "not used" 9 "not used" 8 "not used" 7 "not used" 6 "not used" 5 "not used" 4 "senstivity level-4" 3 "senstivity level-3" 2 "senstivity level-2" 1 "senstivity level-1" 0 "not used";
VAL_ 1173 AVM_Parking_mode 8 "Forced to end" 7 "emergency stop" 6 "Left parking out" 5 "Right parking out" 4 "Left Perpendicular parking" 3 "Right Perpendicular parking" 2 "Left Parallel parking" 1 "Right Parallel parking" 0 "No message";
VAL_ 1173 Hood_Latch_SW 2 "invalid" 1 "Press" 0 "No Request";
VAL_ 1173 RCTA_BUTT 2 "Invalid" 1 "Pressed" 0 "No request";
VAL_ 1173 IVI_Pwroff_req 1 "Request" 0 "No request";
VAL_ 1173 IVI_Trigger_req 1 "Request" 0 "No request";
VAL_ 1173 AVM_Err_STA 1 "Error" 0 "No Error";
VAL_ 1173 IVI_Mute_Sta 1 "Mute On" 0 "Mute Off";
VAL_ 1173 IVI_PTG_USSta_SW 1 "Off" 0 "On";
VAL_ 1173 IVI_WI_MAIN_SW 1 "ON" 0 "OFF";
VAL_ 1173 IVI_RR_Def_Req 1 "Press" 0 "Release";
VAL_ 1173 IVI_Night_Mode_Sta 1 "ON" 0 "OFF";
VAL_ 1173 IVI_Status 1 "Ready" 0 "Not ready";
VAL_ 1173 LVDAMute_BUTT 2 "Invalid" 1 "Pressed" 0 "No request";
VAL_ 1173 CAAS_Sw 2 "Invalid" 1 "Press" 0 "Release";
VAL_ 1173 DSEAT_entryfun_set 1 "ON" 0 "OFF";
VAL_ 1173 DSEAT_anti_set 1 "ON" 0 "OFF";
VAL_ 1173 TPMS_Res_Butt 1 "Press" 0 "Release";
VAL_ 1173 FollowMeSW 1 "Press" 0 "Release";
VAL_ 1173 SetUnlockSingle 1 "Press" 0 "Release";
VAL_ 1173 IVI_PTG_Mode_SW 2 "Invalid" 1 "Press" 0 "No Request";
VAL_ 1173 IVI_PTG_Sta_SW 2 "Invalid" 1 "Press" 0 "Release";
VAL_ 1173 SLG_Sw 2 "invalid" 1 "ON" 0 "OFF";
VAL_ 1173 FS_Off_Sw 2 "invalid" 1 "ON" 0 "OFF";
VAL_ 1173 PSEAT_vent_req 4 "OFF" 3 "Vent3" 2 "Vent2" 1 "Vent1" 0 "No request";
VAL_ 1173 FFogLampSW 1 "ON" 0 "OFF";
VAL_ 1173 DSEAT_vent_req 7 "Not used" 6 "Not used" 5 "Not used" 4 "OFF" 3 "High" 2 "Middle" 1 "Low" 0 "No request";
VAL_ 1173 RFogLampSW 1 "ON" 0 "OFF";
VAL_ 1173 MFRD_N_Bright_Req 127 "invalid" 100 "Max" 0 "Min";
VAL_ 1173 User_p_download 1 "download" 0 "No Request";
VAL_ 1173 HeadLampSW 3 "OFF" 2 "Low beam" 1 "Postion lamp" 0 "AUTO";
VAL_ 1173 NAVI_State 3 "NAVI error" 2 "NAVI good reception" 1 "NAVI no satellite" 0 "No NAVI";
VAL_ 1173 Wifi_Sta_IVI_TBOX 9 "password error" 8 "Connection error" 6 "Internal Error" 5 "no signal" 4 "4 bar" 3 "3 bar" 2 "2 bar" 1 "1 bar" 0 "Invalid";
VAL_ 1173 NAVI_Cam_Dist_info 255 "Invalid" 150 "MAX" 0 "Min";
VAL_ 1173 OFF_AC_MODE 7 "Invalid" 3 "CAMP" 2 "Pet" 1 "ON" 0 "OFF";
VAL_ 1173 IVI_PW_Mode_Req 3 "No request" 2 "ECO" 1 "Sport" 0 "Normal";
VAL_ 1173 User_p_upload 1 "upload" 0 "No Request";
VAL_ 1173 CameraWrn 1 "Warnning enable" 0 "Off";
VAL_ 1173 Wifi_Reset 1 "reset VIG Wifi" 0 "No Request";
VAL_ 1173 IVI_Screen 63 "invalid" 62 "undefined" 29 "undefined" 28 "APS-all" 27 "AVM-all" 26 "Phone:incoming call popup:upper" 25 "Phone:dialer-upper" 24 "Phone:call history-upper" 23 "Phone:contacts-upper" 22 "System setting-Display-all" 21 "System setting-Sound-all" 20 "System setting-Cellular-all" 19 "System setting-Bluetooth-all" 18 "System setting-WiFi-all" 17 "System setting-account-all" 16 "Setting-About-all" 15 "Setting-Software-all" 14 "Setting-Service-all" 13 "Setting-Security-all" 12 "Setting-ADAS-all" 11 "Setting-Doors-all" 10 "Setting-Charging-all" 9 "Setting-Energy-all" 8 "Setting-Spotlight-all" 7 "Navi page-upper" 6 "3rd party app page-upper" 5 "Android auto-upper" 4 "Car play-upper" 3 "All app page-upper" 2 "DropDown menu-upper" 1 "DropDown menu-all" 0 "Home-up";
VAL_ 1173 TurnSwTimeSet 3 "Undefiend" 2 "7 times" 1 "5 times" 0 "3 times";
VAL_ 1173 Pressure_unit 1 "kg/m2" 0 "PSI";
VAL_ 1173 Time_system 1 "24h" 0 "12h";
VAL_ 1173 NAVI_Speed_Limit_A 3 "invalid" 2 "Not Used" 1 "Applicable" 0 "Not Applicable";
VAL_ 1173 Temperature_unit 1 "Fahrenheit" 0 "Celsius";
VAL_ 1173 Distance_unit 1 "mile" 0 "kilometer";
VAL_ 1173 ESC_SW_Cmd 3 "Invaild" 2 "Undefined" 1 "Press" 0 "Release";
VAL_ 1173 IVI_Panel_Act 1 "PRESS" 0 "RELEASE";
VAL_ 1173 sigHvacRearReq 1 "Press" 0 "Release";
VAL_ 1173 FCWMute_BUTT 2 "Invalid" 1 "Pressed" 0 "No request";
VAL_ 1173 LKA_BUTT 2 "Invalid" 1 "Pressed" 0 "No request";
VAL_ 1173 ODAMute_BUTT 2 "Invalid" 1 "Pressed" 0 "No request";
VAL_ 1173 LDWMute_BUTT 2 "Invalid" 1 "Pressed" 0 "No request";
VAL_ 1173 BSDMute_BUTT 2 "Invalid" 1 "Pressed" 0 "No request";
VAL_ 1173 sigWindDirZon3Req 7 "NOT Set / Reserved" 6 "All open" 5 "Face + Screen" 4 "DEFOG" 3 "Foot + Screen" 2 "Foot" 1 "Bilevel" 0 "FACE";
VAL_ 1173 sigAirIntenZon3Req 15 "Invalid" 14 "Reserved" 11 "Reserved" 10 "NOT set" 9 "Level 8" 8 "Level 7" 7 "Level 6" 6 "Level 5" 5 "Level 4" 4 "Level 3" 3 "Level 2" 2 "Level 1" 1 "OFF" 0 "NO display / No request";
VAL_ 1173 sigAirIntenZon1Req 15 "Invalid" 14 "Reserved" 11 "Reserved" 10 "NOT set" 9 "Level 8" 8 "Level 7" 7 "Level 6" 6 "Level 5" 5 "Level 4" 4 "Level 3" 3 "Level 2" 2 "Level 1" 1 "OFF" 0 "NO display / No request";
VAL_ 1173 AEB_BUTT 2 "Invalid" 1 "Pressed" 0 "No request";
VAL_ 1173 sigRecircReq 1 "Press" 0 "Release";
VAL_ 1173 sigHvacReq 1 "ON" 0 "Off / Auto";
VAL_ 1173 sigHvacFrontReq 1 "Press" 0 "Release";
VAL_ 1173 sigDfrstReq 1 "press" 0 "relesase";
VAL_ 1173 L_Drv_ControlCommand 127 "No Request" 100 "Max" 0 "Min";
VAL_ 1173 TPMS_Cali_Butt 1 "press" 0 "relesase";
VAL_ 1173 L_Pas_ControlCommand 127 "No Request" 100 "Max" 0 "Min";
VAL_ 1173 IVI_Unlock_Chg_req 1 "press" 0 "relesase";
VAL_ 1173 L_RLD_ControlCommand 127 "No Request" 100 "Max" 0 "Min";
VAL_ 1173 IVI_Stop_Chg_req 1 "press" 0 "relesase";
VAL_ 1173 L_RRD_ControlCommand 127 "No Request" 100 "Max" 0 "Min";
VAL_ 1173 IVI_Start_Chg_req 1 "press" 0 "relesase";
VAL_ 1173 METER_Malfunc_Sta 2 "Warning flash" 1 "Warning" 0 "Normal";
VAL_ 1173 sigFootReq 1 "press" 0 "relesase";
VAL_ 1173 sigFaceReq 1 "press" 0 "relesase";
VAL_ 1173 Sched_Chg_Start 1 "press" 0 "release";
VAL_ 1173 Sched_Chg_wake 1 "wake" 0 "standby";
VAL_ 1173 Sched_Chg_butt 1 "on" 0 "off";
VAL_ 1173 Sched_Chg_Stop 1 "press" 0 "release";
VAL_ 1173 Sched_Chg_limit 31 "invalid" 26 "~0x1E undefined" 0 "~0x19 50%~100%";
VAL_ 1173 Walkaway_Lock_SW 1 "ON" 0 "OFF";
VAL_ 1173 Approach_Unlock_SW 1 "ON" 0 "OFF";
VAL_ 1173 FalseNPrevent_SW 1 "ON" 0 "OFF";
VAL_ 1173 IVI_CreepSW_Req 1 "Press" 0 "Release";
VAL_ 1173 IVI_PTG_Open_Height 7 "Invalid" 6 "Invalid" 5 "Invalid" 4 "Set by User" 3 "Lv3(80%)" 2 "Lv2(60%)" 1 "Lv1(40%)" 0 "Full Open";
VAL_ 1173 IVI_Req_V2L 1 "Request" 0 "Not request";
VAL_ 1173 Perd_V2L 15 "8hr" 14 "7.5hr" 13 "7hr" 12 "6.5hr" 11 "6hr" 10 "5.5hr" 9 "5hr" 8 "4.5hr" 7 "4hr" 6 "3.5hr" 5 "3hr" 4 "2.5hr" 3 "2hr" 2 "1.5hr" 1 "1hr" 0 "0.5hr";
VAL_ 1173 SOC_V2LLimit 15 "invalid" 14 "undefined" 13 "undefined" 12 "80%" 11 "75%" 10 "70%" 9 "65%" 8 "60%" 7 "55%" 6 "50%" 5 "45%" 4 "40%" 3 "35%" 2 "30%" 1 "25%" 0 "20%";
VAL_ 1183 IVI_Located_STA 3 "Not Used" 2 "3D fix" 1 "2D fix" 0 "No fix";
VAL_ 1183 IVI_Time_Month 15 "Not Used" 14 "Not Used" 13 "Not Used" 0 "invalid";
VAL_ 1249 ReserveChargeOn_Month 15 "Not Used" 14 "Not Used" 13 "Not Used" 0 "invalid";
VAL_ 1249 ReserveChargeOFF_Month 15 "Not Used" 14 "Not Used" 13 "Not Used" 0 "invalid";
VAL_ 1249 Charge_Percent_Set 101 "Failed" 100 "Max" 0 "Min";
VAL_ 1280 NM_FUSION_ERROR_State 8 "BUS OFF_L2" 4 "BUS OFF_L1" 2 "ERROR PASSIVE" 1 "ERROR ACTIVE" 0 "Inactive";
VAL_ 1280 NM_FUSION_Rpt_Msg_Req 1 "Repeat Message State requested" 0 "Repeat Message State not requested";
VAL_ 1280 NM_FUSION_CSB 1 "Start of synchronized shutdown is requested by main coordinator" 0 "Start of synchronized shutdown is not requested by main coordinator";
VAL_ 1280 NM_FUSION_Active_WU 1 "Node has woken up the network (active Wakeup)" 0 "Node has not woken up the network (passive wakeup)";
VAL_ 1280 NM_FUSION_PNI 1 "NM PDU contains Partial Network request information" 0 "NM PDU contains no Partial Network request information";
VAL_ 1283 NM_MCU_R_ERROR_State 8 "BUS OFF_L2" 4 "BUS OFF_L1" 2 "ERROR PASSIVE" 1 "ERROR ACTIVE" 0 "Inactive";
VAL_ 1283 NM_MCU_R_Rpt_Msg_Req 1 "Repeat Message State requested" 0 "Repeat Message State not requested";
VAL_ 1283 NM_MCU_R_CSB 1 "Start of synchronized shutdown is requested by main coordinator" 0 "Start of synchronized shutdown is not requested by main coordinator";
VAL_ 1283 NM_MCU_R_Active_WU 1 "Node has woken up the network (active Wakeup)" 0 "Node has not woken up the network (passive wakeup)";
VAL_ 1283 NM_MCU_R_PNI 1 "NM PDU contains Partial Network request information" 0 "NM PDU contains no Partial Network request information";
VAL_ 1288 NM_MCU_F_ERROR_State 8 "BUS OFF_L2" 4 "BUS OFF_L1" 2 "ERROR PASSIVE" 1 "ERROR ACTIVE" 0 "Inactive";
VAL_ 1288 NM_MCU_F_Rpt_Msg_Req 1 "Repeat Message State requested" 0 "Repeat Message State not requested";
VAL_ 1288 NM_MCU_F_CSB 1 "Start of synchronized shutdown is requested by main coordinator" 0 "Start of synchronized shutdown is not requested by main coordinator";
VAL_ 1288 NM_MCU_F_Active_WU 1 "Node has woken up the network (active Wakeup)" 0 "Node has not woken up the network (passive wakeup)";
VAL_ 1288 NM_MCU_F_PNI 1 "NM PDU contains Partial Network request information" 0 "NM PDU contains no Partial Network request information";
VAL_ 1299 NM_EOP_R_ERROR_State 8 "BUS OFF_L2" 4 "BUS OFF_L1" 2 "ERROR PASSIVE" 1 "ERROR ACTIVE" 0 "Inactive";
VAL_ 1299 NM_EOP_R_Rpt_Msg_Req 1 "Repeat Message State requested" 0 "Repeat Message State not requested";
VAL_ 1299 NM_EOP_R_CSB 1 "Start of synchronized shutdown is requested by main coordinator" 0 "Start of synchronized shutdown is not requested by main coordinator";
VAL_ 1299 NM_EOP_R_Active_WU 1 "Node has woken up the network (active Wakeup)" 0 "Node has not woken up the network (passive wakeup)";
VAL_ 1299 NM_EOP_R_PNI 1 "NM PDU contains Partial Network request information" 0 "NM PDU contains no Partial Network request information";
VAL_ 1304 NM_EOP_F_ERROR_State 8 "BUS OFF_L2" 4 "BUS OFF_L1" 2 "ERROR PASSIVE" 1 "ERROR ACTIVE" 0 "Inactive";
VAL_ 1304 NM_EOP_F_Rpt_Msg_Req 1 "Repeat Message State requested" 0 "Repeat Message State not requested";
VAL_ 1304 NM_EOP_F_CSB 1 "Start of synchronized shutdown is requested by main coordinator" 0 "Start of synchronized shutdown is not requested by main coordinator";
VAL_ 1304 NM_EOP_F_Active_WU 1 "Node has woken up the network (active Wakeup)" 0 "Node has not woken up the network (passive wakeup)";
VAL_ 1304 NM_EOP_F_PNI 1 "NM PDU contains Partial Network request information" 0 "NM PDU contains no Partial Network request information";
VAL_ 1328 NM_BMS_ERROR_State 8 "BUS OFF_L2" 4 "BUS OFF_L1" 2 "ERROR PASSIVE" 1 "ERROR ACTIVE" 0 "Inactive";
VAL_ 1328 NM_BMS_Rpt_Msg_Req 1 "Repeat Message State requested" 0 "Repeat Message State not requested";
VAL_ 1328 NM_BMS_CSB 1 "Start of synchronized shutdown is requested by main coordinator" 0 "Start of synchronized shutdown is not requested by main coordinator";
VAL_ 1328 NM_BMS_Active_WU 1 "Node has woken up the network (active Wakeup)" 0 "Node has not woken up the network (passive wakeup)";
VAL_ 1328 NM_BMS_PNI 1 "NM PDU contains Partial Network request information" 0 "NM PDU contains no Partial Network request information";
VAL_ 1331 NM_CCU_ERROR_State 8 "BUS OFF_L2" 4 "BUS OFF_L1" 2 "ERROR PASSIVE" 1 "ERROR ACTIVE" 0 "Inactive";
VAL_ 1331 NM_CCU_Rpt_Msg_Req 1 "Repeat Message State requested" 0 "Repeat Message State not requested";
VAL_ 1331 NM_CCU_CSB 1 "Start of synchronized shutdown is requested by main coordinator" 0 "Start of synchronized shutdown is not requested by main coordinator";
VAL_ 1331 NM_CCU_Active_WU 1 "Node has woken up the network (active Wakeup)" 0 "Node has not woken up the network (passive wakeup)";
VAL_ 1331 NM_CCU_PNI 1 "NM PDU contains Partial Network request information" 0 "NM PDU contains no Partial Network request information";
VAL_ 1336 NM_Shifter_ERROR_State 8 "BUS OFF_L2" 4 "BUS OFF_L1" 2 "ERROR PASSIVE" 1 "ERROR ACTIVE" 0 "Inactive";
VAL_ 1336 NM_Shifter_Rpt_Msg_Req 1 "Repeat Message State requested" 0 "Repeat Message State not requested";
VAL_ 1336 NM_Shifter_CSB 1 "Start of synchronized shutdown is requested by main coordinator" 0 "Start of synchronized shutdown is not requested by main coordinator";
VAL_ 1336 NM_Shifter_Active_WU 1 "Node has woken up the network (active Wakeup)" 0 "Node has not woken up the network (passive wakeup)";
VAL_ 1336 NM_Shifter_PNI 1 "NM PDU contains Partial Network request information" 0 "NM PDU contains no Partial Network request information";
VAL_ 1080 OTA_Up_Backcount 122 "Invalid" 121 "No action" 0 "~0x78 0s~120s";
VAL_ 1080 OTA_Lock_Req 1 "Lock Request" 0 "No action";
VAL_ 1080 OTA_Updating_ECU 30 "Invalid" 29 "HMI" 28 "W_PTC" 27 "EBM" 26 "AIRPTC" 25 "E_Compressor" 24 "Shifter" 23 "TELLTALE" 22 "MRR" 21 "SRR_M" 20 "FCM" 19 "EPS" 18 "EOP_F" 17 "EOP_R" 16 "MCU_F" 15 "MCU_R" 14 "eBST" 13 "ESC" 12 "APM" 11 "PSEAT" 10 "DSEAT" 9 "PTG" 8 "CCU" 7 "BMS" 6 "DKC" 5 "Zone_Dr" 4 "Zone_Fr" 3 "T-Box" 2 "IVI" 1 "FDC" 0 "No action";
VAL_ 1080 OTA_Update_Available 1 "Ready for Update" 0 "Not Ready";
VAL_ 1080 OTA_InVehicle_FW 2 "FW Need Update" 1 "FW Up to Date" 0 "Not Confirm";
VAL_ 1080 OTA_DL_Available 1 "Ready for Download" 0 "Not Ready";
VAL_ 1080 OTA_Mode 1 "OTA mode" 0 "Normal mode";
VAL_ 1080 OTA_Network_Type 3 "Undefine" 2 "WiFi" 1 "LTE" 0 "Network Not Available";
VAL_ 1080 OTA_MDA_Status 14 "Undefine" 13 "OTA Task Finished" 12 "Vehicle Update Complete" 11 "Update Failed" 10 "Download Failed" 9 "Countdown" 8 "Download Suspend" 7 "Vehicle Roll-Back" 6 "Vehicle Updating" 5 "Wait Update" 4 "Campaign Downloading" 3 "Wait Download" 2 "Ask Campaign" 1 "Ready" 0 "Not Ready";
VAL_ 1080 OTA_Progress_Rate 102 "Invalid" 101 "Not in progress" 100 "100%" 99 "99%" 0 "~0x64 0%~100%";
VAL_ 1080 OTA_TBOXResetReq 1 "Request reset" 0 "No request";
VAL_ 552 CCV4_MoveEnable 1 "ReqMotorMove" 0 "NoReq";
VAL_ 552 CCV4_ReqMovePos 1 "Open Port 1 to Port 4, Port 2 to port 3" 0 "Open Port 1 to Port 2, Port 3 to port 4";
VAL_ 552 EWP1_Default_Operation_EWP_Rq 1 "Default Operation" 0 "Default Sleep";
VAL_ 552 EWP3_Default_Operation_EWP_Rq 1 "Default Operation" 0 "Default Sleep";
VAL_ 552 BDC_1_MoveEnable 1 "ReqMotorMove" 0 "NoReq";
VAL_ 552 EWP2_Default_Operation_EWP_Rq 1 "Default Operation" 0 "Default Sleep";
VAL_ 552 EXV_Cmd_Move_Enbl 1 "Move to Commanded Position" 0 "Ignore Commanded Position";
VAL_ 552 EXV2_Cmd_Move_Enbl 1 "Move to Commanded Position" 0 "Ignore Commanded Position";
VAL_ 552 EXV2_Cmd_Init_Rq 7 "not defined" 6 "not defined" 5 "not defined" 4 "not defined" 3 "not defined" 2 "waiting for Sequence to finish" 1 "start Init-Sequence" 0 "No Request";
VAL_ 552 EXV_Cmd_Init_Rq 7 "not defined" 6 "not defined" 5 "not defined" 4 "not defined" 3 "not defined" 2 "waiting for Sequence to finish" 1 "start Init-Sequence" 0 "No Request";
VAL_ 552 EWP1_RPM_Target_EWP_Rq 255 "Invalid" 254 "max speed rpm" 253 "max speed rpm" 252 "max speed rpm" 251 "max speed rpm" 250 "linearly changed from min speed to max speed" 249 "linearly changed from min speed to max speed" 248 "linearly changed from min speed to max speed" 247 "linearly changed from min speed to max speed" 246 "linearly changed from min speed to max speed" 245 "linearly changed from min speed to max speed" 244 "linearly changed from min speed to max speed" 243 "linearly changed from min speed to max speed" 242 "linearly changed from min speed to max speed" 241 "linearly changed from min speed to max speed" 240 "linearly changed from min speed to max speed" 239 "linearly changed from min speed to max speed" 238 "linearly changed from min speed to max speed" 237 "linearly changed from min speed to max speed" 236 "linearly changed from min speed to max speed" 235 "linearly changed from min speed to max speed" 234 "linearly changed from min speed to max speed" 233 "linearly changed from min speed to max speed" 232 "linearly changed from min speed to max speed" 231 "linearly changed from min speed to max speed" 230 "linearly changed from min speed to max speed" 229 "linearly changed from min speed to max speed" 228 "linearly changed from min speed to max speed" 227 "linearly changed from min speed to max speed" 226 "linearly changed from min speed to max speed" 225 "linearly changed from min speed to max speed" 224 "linearly changed from min speed to max speed" 223 "linearly changed from min speed to max speed" 222 "linearly changed from min speed to max speed" 221 "linearly changed from min speed to max speed" 220 "linearly changed from min speed to max speed" 219 "linearly changed from min speed to max speed" 218 "linearly changed from min speed to max speed" 217 "linearly changed from min speed to max speed" 216 "linearly changed from min speed to max speed" 215 "linearly changed from min speed to max speed" 214 "linearly changed from min speed to max speed" 213 "linearly changed from min speed to max speed" 212 "linearly changed from min speed to max speed" 211 "linearly changed from min speed to max speed" 210 "linearly changed from min speed to max speed" 209 "linearly changed from min speed to max speed" 208 "linearly changed from min speed to max speed" 207 "linearly changed from min speed to max speed" 206 "linearly changed from min speed to max speed" 205 "linearly changed from min speed to max speed" 204 "linearly changed from min speed to max speed" 203 "linearly changed from min speed to max speed" 202 "linearly changed from min speed to max speed" 201 "linearly changed from min speed to max speed" 200 "linearly changed from min speed to max speed" 199 "linearly changed from min speed to max speed" 198 "linearly changed from min speed to max speed" 197 "linearly changed from min speed to max speed" 196 "linearly changed from min speed to max speed" 195 "linearly changed from min speed to max speed" 194 "linearly changed from min speed to max speed" 193 "linearly changed from min speed to max speed" 192 "linearly changed from min speed to max speed" 191 "linearly changed from min speed to max speed" 190 "linearly changed from min speed to max speed" 189 "linearly changed from min speed to max speed" 188 "linearly changed from min speed to max speed" 187 "linearly changed from min speed to max speed" 186 "linearly changed from min speed to max speed" 185 "linearly changed from min speed to max speed" 184 "linearly changed from min speed to max speed" 183 "linearly changed from min speed to max speed" 182 "linearly changed from min speed to max speed" 181 "linearly changed from min speed to max speed" 180 "linearly changed from min speed to max speed" 179 "linearly changed from min speed to max speed" 178 "linearly changed from min speed to max speed" 177 "linearly changed from min speed to max speed" 176 "linearly changed from min speed to max speed" 175 "linearly changed from min speed to max speed" 174 "linearly changed from min speed to max speed" 173 "linearly changed from min speed to max speed" 172 "linearly changed from min speed to max speed" 171 "linearly changed from min speed to max speed" 170 "linearly changed from min speed to max speed" 169 "linearly changed from min speed to max speed" 168 "linearly changed from min speed to max speed" 167 "linearly changed from min speed to max speed" 166 "linearly changed from min speed to max speed" 165 "linearly changed from min speed to max speed" 164 "linearly changed from min speed to max speed" 163 "linearly changed from min speed to max speed" 162 "linearly changed from min speed to max speed" 161 "linearly changed from min speed to max speed" 160 "linearly changed from min speed to max speed" 159 "linearly changed from min speed to max speed" 158 "linearly changed from min speed to max speed" 157 "linearly changed from min speed to max speed" 156 "linearly changed from min speed to max speed" 155 "linearly changed from min speed to max speed" 154 "linearly changed from min speed to max speed" 153 "linearly changed from min speed to max speed" 152 "linearly changed from min speed to max speed" 151 "linearly changed from min speed to max speed" 150 "linearly changed from min speed to max speed" 149 "linearly changed from min speed to max speed" 148 "linearly changed from min speed to max speed" 147 "linearly changed from min speed to max speed" 146 "linearly changed from min speed to max speed" 145 "linearly changed from min speed to max speed" 144 "linearly changed from min speed to max speed" 143 "linearly changed from min speed to max speed" 142 "linearly changed from min speed to max speed" 141 "linearly changed from min speed to max speed" 140 "linearly changed from min speed to max speed" 139 "linearly changed from min speed to max speed" 138 "linearly changed from min speed to max speed" 137 "linearly changed from min speed to max speed" 136 "linearly changed from min speed to max speed" 135 "linearly changed from min speed to max speed" 134 "linearly changed from min speed to max speed" 133 "linearly changed from min speed to max speed" 132 "linearly changed from min speed to max speed" 131 "linearly changed from min speed to max speed" 130 "linearly changed from min speed to max speed" 129 "linearly changed from min speed to max speed" 128 "linearly changed from min speed to max speed" 127 "linearly changed from min speed to max speed" 126 "linearly changed from min speed to max speed" 125 "linearly changed from min speed to max speed" 124 "linearly changed from min speed to max speed" 123 "linearly changed from min speed to max speed" 122 "linearly changed from min speed to max speed" 121 "linearly changed from min speed to max speed" 120 "linearly changed from min speed to max speed" 119 "linearly changed from min speed to max speed" 118 "linearly changed from min speed to max speed" 117 "linearly changed from min speed to max speed" 116 "linearly changed from min speed to max speed" 115 "linearly changed from min speed to max speed" 114 "linearly changed from min speed to max speed" 113 "linearly changed from min speed to max speed" 112 "linearly changed from min speed to max speed" 111 "linearly changed from min speed to max speed" 110 "linearly changed from min speed to max speed" 109 "linearly changed from min speed to max speed" 108 "linearly changed from min speed to max speed" 107 "linearly changed from min speed to max speed" 106 "linearly changed from min speed to max speed" 105 "linearly changed from min speed to max speed" 104 "linearly changed from min speed to max speed" 103 "linearly changed from min speed to max speed" 102 "linearly changed from min speed to max speed" 101 "linearly changed from min speed to max speed" 100 "linearly changed from min speed to max speed" 99 "linearly changed from min speed to max speed" 98 "linearly changed from min speed to max speed" 97 "linearly changed from min speed to max speed" 96 "linearly changed from min speed to max speed" 95 "linearly changed from min speed to max speed" 94 "linearly changed from min speed to max speed" 93 "linearly changed from min speed to max speed" 92 "linearly changed from min speed to max speed" 91 "linearly changed from min speed to max speed" 90 "linearly changed from min speed to max speed" 89 "linearly changed from min speed to max speed" 88 "linearly changed from min speed to max speed" 87 "linearly changed from min speed to max speed" 86 "linearly changed from min speed to max speed" 85 "linearly changed from min speed to max speed" 84 "linearly changed from min speed to max speed" 83 "linearly changed from min speed to max speed" 82 "linearly changed from min speed to max speed" 81 "linearly changed from min speed to max speed" 80 "linearly changed from min speed to max speed" 79 "linearly changed from min speed to max speed" 78 "linearly changed from min speed to max speed" 77 "linearly changed from min speed to max speed" 76 "linearly changed from min speed to max speed" 75 "linearly changed from min speed to max speed" 74 "linearly changed from min speed to max speed" 73 "linearly changed from min speed to max speed" 72 "linearly changed from min speed to max speed" 71 "linearly changed from min speed to max speed" 70 "linearly changed from min speed to max speed" 69 "linearly changed from min speed to max speed" 68 "linearly changed from min speed to max speed" 67 "linearly changed from min speed to max speed" 66 "linearly changed from min speed to max speed" 65 "linearly changed from min speed to max speed" 64 "linearly changed from min speed to max speed" 63 "linearly changed from min speed to max speed" 62 "linearly changed from min speed to max speed" 61 "linearly changed from min speed to max speed" 60 "linearly changed from min speed to max speed" 59 "linearly changed from min speed to max speed" 58 "linearly changed from min speed to max speed" 57 "linearly changed from min speed to max speed" 56 "linearly changed from min speed to max speed" 55 "linearly changed from min speed to max speed" 54 "linearly changed from min speed to max speed" 53 "linearly changed from min speed to max speed" 52 "linearly changed from min speed to max speed" 51 "linearly changed from min speed to max speed" 50 "linearly changed from min speed to max speed" 49 "min speed rpm" 48 "min speed rpm" 47 "min speed rpm" 46 "min speed rpm" 45 "min speed rpm" 44 "min speed rpm" 43 "min speed rpm" 42 "min speed rpm" 41 "min speed rpm" 40 "min speed rpm" 39 "min speed rpm" 38 "min speed rpm" 37 "min speed rpm" 36 "min speed rpm" 35 "min speed rpm" 34 "min speed rpm" 33 "min speed rpm" 32 "min speed rpm" 31 "min speed rpm" 30 "min speed rpm" 29 "min speed rpm" 28 "min speed rpm" 27 "min speed rpm" 26 "min speed rpm" 25 "min speed rpm" 24 "min speed rpm" 23 "min speed rpm" 22 "min speed rpm" 21 "min speed rpm" 20 "min speed rpm" 19 "min speed rpm" 18 "min speed rpm" 17 "min speed rpm" 16 "min speed rpm" 15 "min speed rpm" 14 "min speed rpm" 13 "min speed rpm" 12 "min speed rpm" 11 "min speed rpm" 10 "min speed rpm" 9 "min speed rpm" 8 "min speed rpm" 7 "min speed rpm" 6 "min speed rpm" 5 "min speed rpm" 4 "min speed rpm" 3 "0 rpm" 2 "0 rpm" 1 "0 rpm" 0 "0 rpm";
VAL_ 552 EWP3_RPM_Target_EWP_Rq 255 "Invalid" 254 "max speed rpm" 253 "max speed rpm" 252 "max speed rpm" 251 "max speed rpm" 250 "linearly changed from min speed to max speed" 249 "linearly changed from min speed to max speed" 248 "linearly changed from min speed to max speed" 247 "linearly changed from min speed to max speed" 246 "linearly changed from min speed to max speed" 245 "linearly changed from min speed to max speed" 244 "linearly changed from min speed to max speed" 243 "linearly changed from min speed to max speed" 242 "linearly changed from min speed to max speed" 241 "linearly changed from min speed to max speed" 240 "linearly changed from min speed to max speed" 239 "linearly changed from min speed to max speed" 238 "linearly changed from min speed to max speed" 237 "linearly changed from min speed to max speed" 236 "linearly changed from min speed to max speed" 235 "linearly changed from min speed to max speed" 234 "linearly changed from min speed to max speed" 233 "linearly changed from min speed to max speed" 232 "linearly changed from min speed to max speed" 231 "linearly changed from min speed to max speed" 230 "linearly changed from min speed to max speed" 229 "linearly changed from min speed to max speed" 228 "linearly changed from min speed to max speed" 227 "linearly changed from min speed to max speed" 226 "linearly changed from min speed to max speed" 225 "linearly changed from min speed to max speed" 224 "linearly changed from min speed to max speed" 223 "linearly changed from min speed to max speed" 222 "linearly changed from min speed to max speed" 221 "linearly changed from min speed to max speed" 220 "linearly changed from min speed to max speed" 219 "linearly changed from min speed to max speed" 218 "linearly changed from min speed to max speed" 217 "linearly changed from min speed to max speed" 216 "linearly changed from min speed to max speed" 215 "linearly changed from min speed to max speed" 214 "linearly changed from min speed to max speed" 213 "linearly changed from min speed to max speed" 212 "linearly changed from min speed to max speed" 211 "linearly changed from min speed to max speed" 210 "linearly changed from min speed to max speed" 209 "linearly changed from min speed to max speed" 208 "linearly changed from min speed to max speed" 207 "linearly changed from min speed to max speed" 206 "linearly changed from min speed to max speed" 205 "linearly changed from min speed to max speed" 204 "linearly changed from min speed to max speed" 203 "linearly changed from min speed to max speed" 202 "linearly changed from min speed to max speed" 201 "linearly changed from min speed to max speed" 200 "linearly changed from min speed to max speed" 199 "linearly changed from min speed to max speed" 198 "linearly changed from min speed to max speed" 197 "linearly changed from min speed to max speed" 196 "linearly changed from min speed to max speed" 195 "linearly changed from min speed to max speed" 194 "linearly changed from min speed to max speed" 193 "linearly changed from min speed to max speed" 192 "linearly changed from min speed to max speed" 191 "linearly changed from min speed to max speed" 190 "linearly changed from min speed to max speed" 189 "linearly changed from min speed to max speed" 188 "linearly changed from min speed to max speed" 187 "linearly changed from min speed to max speed" 186 "linearly changed from min speed to max speed" 185 "linearly changed from min speed to max speed" 184 "linearly changed from min speed to max speed" 183 "linearly changed from min speed to max speed" 182 "linearly changed from min speed to max speed" 181 "linearly changed from min speed to max speed" 180 "linearly changed from min speed to max speed" 179 "linearly changed from min speed to max speed" 178 "linearly changed from min speed to max speed" 177 "linearly changed from min speed to max speed" 176 "linearly changed from min speed to max speed" 175 "linearly changed from min speed to max speed" 174 "linearly changed from min speed to max speed" 173 "linearly changed from min speed to max speed" 172 "linearly changed from min speed to max speed" 171 "linearly changed from min speed to max speed" 170 "linearly changed from min speed to max speed" 169 "linearly changed from min speed to max speed" 168 "linearly changed from min speed to max speed" 167 "linearly changed from min speed to max speed" 166 "linearly changed from min speed to max speed" 165 "linearly changed from min speed to max speed" 164 "linearly changed from min speed to max speed" 163 "linearly changed from min speed to max speed" 162 "linearly changed from min speed to max speed" 161 "linearly changed from min speed to max speed" 160 "linearly changed from min speed to max speed" 159 "linearly changed from min speed to max speed" 158 "linearly changed from min speed to max speed" 157 "linearly changed from min speed to max speed" 156 "linearly changed from min speed to max speed" 155 "linearly changed from min speed to max speed" 154 "linearly changed from min speed to max speed" 153 "linearly changed from min speed to max speed" 152 "linearly changed from min speed to max speed" 151 "linearly changed from min speed to max speed" 150 "linearly changed from min speed to max speed" 149 "linearly changed from min speed to max speed" 148 "linearly changed from min speed to max speed" 147 "linearly changed from min speed to max speed" 146 "linearly changed from min speed to max speed" 145 "linearly changed from min speed to max speed" 144 "linearly changed from min speed to max speed" 143 "linearly changed from min speed to max speed" 142 "linearly changed from min speed to max speed" 141 "linearly changed from min speed to max speed" 140 "linearly changed from min speed to max speed" 139 "linearly changed from min speed to max speed" 138 "linearly changed from min speed to max speed" 137 "linearly changed from min speed to max speed" 136 "linearly changed from min speed to max speed" 135 "linearly changed from min speed to max speed" 134 "linearly changed from min speed to max speed" 133 "linearly changed from min speed to max speed" 132 "linearly changed from min speed to max speed" 131 "linearly changed from min speed to max speed" 130 "linearly changed from min speed to max speed" 129 "linearly changed from min speed to max speed" 128 "linearly changed from min speed to max speed" 127 "linearly changed from min speed to max speed" 126 "linearly changed from min speed to max speed" 125 "linearly changed from min speed to max speed" 124 "linearly changed from min speed to max speed" 123 "linearly changed from min speed to max speed" 122 "linearly changed from min speed to max speed" 121 "linearly changed from min speed to max speed" 120 "linearly changed from min speed to max speed" 119 "linearly changed from min speed to max speed" 118 "linearly changed from min speed to max speed" 117 "linearly changed from min speed to max speed" 116 "linearly changed from min speed to max speed" 115 "linearly changed from min speed to max speed" 114 "linearly changed from min speed to max speed" 113 "linearly changed from min speed to max speed" 112 "linearly changed from min speed to max speed" 111 "linearly changed from min speed to max speed" 110 "linearly changed from min speed to max speed" 109 "linearly changed from min speed to max speed" 108 "linearly changed from min speed to max speed" 107 "linearly changed from min speed to max speed" 106 "linearly changed from min speed to max speed" 105 "linearly changed from min speed to max speed" 104 "linearly changed from min speed to max speed" 103 "linearly changed from min speed to max speed" 102 "linearly changed from min speed to max speed" 101 "linearly changed from min speed to max speed" 100 "linearly changed from min speed to max speed" 99 "linearly changed from min speed to max speed" 98 "linearly changed from min speed to max speed" 97 "linearly changed from min speed to max speed" 96 "linearly changed from min speed to max speed" 95 "linearly changed from min speed to max speed" 94 "linearly changed from min speed to max speed" 93 "linearly changed from min speed to max speed" 92 "linearly changed from min speed to max speed" 91 "linearly changed from min speed to max speed" 90 "linearly changed from min speed to max speed" 89 "linearly changed from min speed to max speed" 88 "linearly changed from min speed to max speed" 87 "linearly changed from min speed to max speed" 86 "linearly changed from min speed to max speed" 85 "linearly changed from min speed to max speed" 84 "linearly changed from min speed to max speed" 83 "linearly changed from min speed to max speed" 82 "linearly changed from min speed to max speed" 81 "linearly changed from min speed to max speed" 80 "linearly changed from min speed to max speed" 79 "linearly changed from min speed to max speed" 78 "linearly changed from min speed to max speed" 77 "linearly changed from min speed to max speed" 76 "linearly changed from min speed to max speed" 75 "linearly changed from min speed to max speed" 74 "linearly changed from min speed to max speed" 73 "linearly changed from min speed to max speed" 72 "linearly changed from min speed to max speed" 71 "linearly changed from min speed to max speed" 70 "linearly changed from min speed to max speed" 69 "linearly changed from min speed to max speed" 68 "linearly changed from min speed to max speed" 67 "linearly changed from min speed to max speed" 66 "linearly changed from min speed to max speed" 65 "linearly changed from min speed to max speed" 64 "linearly changed from min speed to max speed" 63 "linearly changed from min speed to max speed" 62 "linearly changed from min speed to max speed" 61 "linearly changed from min speed to max speed" 60 "linearly changed from min speed to max speed" 59 "linearly changed from min speed to max speed" 58 "linearly changed from min speed to max speed" 57 "linearly changed from min speed to max speed" 56 "linearly changed from min speed to max speed" 55 "linearly changed from min speed to max speed" 54 "linearly changed from min speed to max speed" 53 "linearly changed from min speed to max speed" 52 "linearly changed from min speed to max speed" 51 "linearly changed from min speed to max speed" 50 "linearly changed from min speed to max speed" 49 "min speed rpm" 48 "min speed rpm" 47 "min speed rpm" 46 "min speed rpm" 45 "min speed rpm" 44 "min speed rpm" 43 "min speed rpm" 42 "min speed rpm" 41 "min speed rpm" 40 "min speed rpm" 39 "min speed rpm" 38 "min speed rpm" 37 "min speed rpm" 36 "min speed rpm" 35 "min speed rpm" 34 "min speed rpm" 33 "min speed rpm" 32 "min speed rpm" 31 "min speed rpm" 30 "min speed rpm" 29 "min speed rpm" 28 "min speed rpm" 27 "min speed rpm" 26 "min speed rpm" 25 "min speed rpm" 24 "min speed rpm" 23 "min speed rpm" 22 "min speed rpm" 21 "min speed rpm" 20 "min speed rpm" 19 "min speed rpm" 18 "min speed rpm" 17 "min speed rpm" 16 "min speed rpm" 15 "min speed rpm" 14 "min speed rpm" 13 "min speed rpm" 12 "min speed rpm" 11 "min speed rpm" 10 "min speed rpm" 9 "min speed rpm" 8 "min speed rpm" 7 "min speed rpm" 6 "min speed rpm" 5 "min speed rpm" 4 "min speed rpm" 3 "0 rpm" 2 "0 rpm" 1 "0 rpm" 0 "0 rpm";
VAL_ 552 EWP2_RPM_Target_EWP_Rq 255 "Invalid" 254 "max speed rpm" 253 "max speed rpm" 252 "max speed rpm" 251 "max speed rpm" 250 "linearly changed from min speed to max speed" 249 "linearly changed from min speed to max speed" 248 "linearly changed from min speed to max speed" 247 "linearly changed from min speed to max speed" 246 "linearly changed from min speed to max speed" 245 "linearly changed from min speed to max speed" 244 "linearly changed from min speed to max speed" 243 "linearly changed from min speed to max speed" 242 "linearly changed from min speed to max speed" 241 "linearly changed from min speed to max speed" 240 "linearly changed from min speed to max speed" 239 "linearly changed from min speed to max speed" 238 "linearly changed from min speed to max speed" 237 "linearly changed from min speed to max speed" 236 "linearly changed from min speed to max speed" 235 "linearly changed from min speed to max speed" 234 "linearly changed from min speed to max speed" 233 "linearly changed from min speed to max speed" 232 "linearly changed from min speed to max speed" 231 "linearly changed from min speed to max speed" 230 "linearly changed from min speed to max speed" 229 "linearly changed from min speed to max speed" 228 "linearly changed from min speed to max speed" 227 "linearly changed from min speed to max speed" 226 "linearly changed from min speed to max speed" 225 "linearly changed from min speed to max speed" 224 "linearly changed from min speed to max speed" 223 "linearly changed from min speed to max speed" 222 "linearly changed from min speed to max speed" 221 "linearly changed from min speed to max speed" 220 "linearly changed from min speed to max speed" 219 "linearly changed from min speed to max speed" 218 "linearly changed from min speed to max speed" 217 "linearly changed from min speed to max speed" 216 "linearly changed from min speed to max speed" 215 "linearly changed from min speed to max speed" 214 "linearly changed from min speed to max speed" 213 "linearly changed from min speed to max speed" 212 "linearly changed from min speed to max speed" 211 "linearly changed from min speed to max speed" 210 "linearly changed from min speed to max speed" 209 "linearly changed from min speed to max speed" 208 "linearly changed from min speed to max speed" 207 "linearly changed from min speed to max speed" 206 "linearly changed from min speed to max speed" 205 "linearly changed from min speed to max speed" 204 "linearly changed from min speed to max speed" 203 "linearly changed from min speed to max speed" 202 "linearly changed from min speed to max speed" 201 "linearly changed from min speed to max speed" 200 "linearly changed from min speed to max speed" 199 "linearly changed from min speed to max speed" 198 "linearly changed from min speed to max speed" 197 "linearly changed from min speed to max speed" 196 "linearly changed from min speed to max speed" 195 "linearly changed from min speed to max speed" 194 "linearly changed from min speed to max speed" 193 "linearly changed from min speed to max speed" 192 "linearly changed from min speed to max speed" 191 "linearly changed from min speed to max speed" 190 "linearly changed from min speed to max speed" 189 "linearly changed from min speed to max speed" 188 "linearly changed from min speed to max speed" 187 "linearly changed from min speed to max speed" 186 "linearly changed from min speed to max speed" 185 "linearly changed from min speed to max speed" 184 "linearly changed from min speed to max speed" 183 "linearly changed from min speed to max speed" 182 "linearly changed from min speed to max speed" 181 "linearly changed from min speed to max speed" 180 "linearly changed from min speed to max speed" 179 "linearly changed from min speed to max speed" 178 "linearly changed from min speed to max speed" 177 "linearly changed from min speed to max speed" 176 "linearly changed from min speed to max speed" 175 "linearly changed from min speed to max speed" 174 "linearly changed from min speed to max speed" 173 "linearly changed from min speed to max speed" 172 "linearly changed from min speed to max speed" 171 "linearly changed from min speed to max speed" 170 "linearly changed from min speed to max speed" 169 "linearly changed from min speed to max speed" 168 "linearly changed from min speed to max speed" 167 "linearly changed from min speed to max speed" 166 "linearly changed from min speed to max speed" 165 "linearly changed from min speed to max speed" 164 "linearly changed from min speed to max speed" 163 "linearly changed from min speed to max speed" 162 "linearly changed from min speed to max speed" 161 "linearly changed from min speed to max speed" 160 "linearly changed from min speed to max speed" 159 "linearly changed from min speed to max speed" 158 "linearly changed from min speed to max speed" 157 "linearly changed from min speed to max speed" 156 "linearly changed from min speed to max speed" 155 "linearly changed from min speed to max speed" 154 "linearly changed from min speed to max speed" 153 "linearly changed from min speed to max speed" 152 "linearly changed from min speed to max speed" 151 "linearly changed from min speed to max speed" 150 "linearly changed from min speed to max speed" 149 "linearly changed from min speed to max speed" 148 "linearly changed from min speed to max speed" 147 "linearly changed from min speed to max speed" 146 "linearly changed from min speed to max speed" 145 "linearly changed from min speed to max speed" 144 "linearly changed from min speed to max speed" 143 "linearly changed from min speed to max speed" 142 "linearly changed from min speed to max speed" 141 "linearly changed from min speed to max speed" 140 "linearly changed from min speed to max speed" 139 "linearly changed from min speed to max speed" 138 "linearly changed from min speed to max speed" 137 "linearly changed from min speed to max speed" 136 "linearly changed from min speed to max speed" 135 "linearly changed from min speed to max speed" 134 "linearly changed from min speed to max speed" 133 "linearly changed from min speed to max speed" 132 "linearly changed from min speed to max speed" 131 "linearly changed from min speed to max speed" 130 "linearly changed from min speed to max speed" 129 "linearly changed from min speed to max speed" 128 "linearly changed from min speed to max speed" 127 "linearly changed from min speed to max speed" 126 "linearly changed from min speed to max speed" 125 "linearly changed from min speed to max speed" 124 "linearly changed from min speed to max speed" 123 "linearly changed from min speed to max speed" 122 "linearly changed from min speed to max speed" 121 "linearly changed from min speed to max speed" 120 "linearly changed from min speed to max speed" 119 "linearly changed from min speed to max speed" 118 "linearly changed from min speed to max speed" 117 "linearly changed from min speed to max speed" 116 "linearly changed from min speed to max speed" 115 "linearly changed from min speed to max speed" 114 "linearly changed from min speed to max speed" 113 "linearly changed from min speed to max speed" 112 "linearly changed from min speed to max speed" 111 "linearly changed from min speed to max speed" 110 "linearly changed from min speed to max speed" 109 "linearly changed from min speed to max speed" 108 "linearly changed from min speed to max speed" 107 "linearly changed from min speed to max speed" 106 "linearly changed from min speed to max speed" 105 "linearly changed from min speed to max speed" 104 "linearly changed from min speed to max speed" 103 "linearly changed from min speed to max speed" 102 "linearly changed from min speed to max speed" 101 "linearly changed from min speed to max speed" 100 "linearly changed from min speed to max speed" 99 "linearly changed from min speed to max speed" 98 "linearly changed from min speed to max speed" 97 "linearly changed from min speed to max speed" 96 "linearly changed from min speed to max speed" 95 "linearly changed from min speed to max speed" 94 "linearly changed from min speed to max speed" 93 "linearly changed from min speed to max speed" 92 "linearly changed from min speed to max speed" 91 "linearly changed from min speed to max speed" 90 "linearly changed from min speed to max speed" 89 "linearly changed from min speed to max speed" 88 "linearly changed from min speed to max speed" 87 "linearly changed from min speed to max speed" 86 "linearly changed from min speed to max speed" 85 "linearly changed from min speed to max speed" 84 "linearly changed from min speed to max speed" 83 "linearly changed from min speed to max speed" 82 "linearly changed from min speed to max speed" 81 "linearly changed from min speed to max speed" 80 "linearly changed from min speed to max speed" 79 "linearly changed from min speed to max speed" 78 "linearly changed from min speed to max speed" 77 "linearly changed from min speed to max speed" 76 "linearly changed from min speed to max speed" 75 "linearly changed from min speed to max speed" 74 "linearly changed from min speed to max speed" 73 "linearly changed from min speed to max speed" 72 "linearly changed from min speed to max speed" 71 "linearly changed from min speed to max speed" 70 "linearly changed from min speed to max speed" 69 "linearly changed from min speed to max speed" 68 "linearly changed from min speed to max speed" 67 "linearly changed from min speed to max speed" 66 "linearly changed from min speed to max speed" 65 "linearly changed from min speed to max speed" 64 "linearly changed from min speed to max speed" 63 "linearly changed from min speed to max speed" 62 "linearly changed from min speed to max speed" 61 "linearly changed from min speed to max speed" 60 "linearly changed from min speed to max speed" 59 "linearly changed from min speed to max speed" 58 "linearly changed from min speed to max speed" 57 "linearly changed from min speed to max speed" 56 "linearly changed from min speed to max speed" 55 "linearly changed from min speed to max speed" 54 "linearly changed from min speed to max speed" 53 "linearly changed from min speed to max speed" 52 "linearly changed from min speed to max speed" 51 "linearly changed from min speed to max speed" 50 "linearly changed from min speed to max speed" 49 "min speed rpm" 48 "min speed rpm" 47 "min speed rpm" 46 "min speed rpm" 45 "min speed rpm" 44 "min speed rpm" 43 "min speed rpm" 42 "min speed rpm" 41 "min speed rpm" 40 "min speed rpm" 39 "min speed rpm" 38 "min speed rpm" 37 "min speed rpm" 36 "min speed rpm" 35 "min speed rpm" 34 "min speed rpm" 33 "min speed rpm" 32 "min speed rpm" 31 "min speed rpm" 30 "min speed rpm" 29 "min speed rpm" 28 "min speed rpm" 27 "min speed rpm" 26 "min speed rpm" 25 "min speed rpm" 24 "min speed rpm" 23 "min speed rpm" 22 "min speed rpm" 21 "min speed rpm" 20 "min speed rpm" 19 "min speed rpm" 18 "min speed rpm" 17 "min speed rpm" 16 "min speed rpm" 15 "min speed rpm" 14 "min speed rpm" 13 "min speed rpm" 12 "min speed rpm" 11 "min speed rpm" 10 "min speed rpm" 9 "min speed rpm" 8 "min speed rpm" 7 "min speed rpm" 6 "min speed rpm" 5 "min speed rpm" 4 "min speed rpm" 3 "0 rpm" 2 "0 rpm" 1 "0 rpm" 0 "0 rpm";
VAL_ 552 FWiperAS 1 "Not at Stop Position" 0 "Stop Position";
VAL_ 552 FWiperProtection 1 "In protection" 0 "Not in Protectio";
VAL_ 552 ChargeInletLockSta 1 "Lock" 0 "Unlock";
VAL_ 552 AGS_Actuator_Blocked 1 "ERROR" 0 "NO_ERROR";
VAL_ 552 AGS_Actuator_Fault 1 "ERROR" 0 "NO_ERROR";
VAL_ 552 AGS_Calibration_Active 1 "Caliberation_Process_active" 0 "Caliberation_process_inactive";
VAL_ 552 AGS_Calibration_Indicated 1 "CALIBRATION_REQ" 0 "NO_CALIBRATION";
VAL_ 552 AGS_Electrical_Error 1 "ERROR" 0 "NO_ERROR";
VAL_ 552 AGS_Sensor_Error 1 "ERROR" 0 "NO_ERROR";
VAL_ 552 AGS_Temperature_Error 1 "ERROR" 0 "NO_ERROR";
VAL_ 552 AGS_Low_Voltage_Error 1 "ERROR" 0 "NO_Voltage_ERROR";
VAL_ 552 AGS_Actual_Position 240 "90^Deg" 208 "78^Deg" 176 "66^Deg" 144 "54^Deg" 112 "42^Deg" 80 "30^Deg" 48 "18^Deg" 16 "6^Deg" 224 "84^Deg" 192 "72^Deg" 160 "60^Deg" 128 "48^Deg" 96 "36^Deg" 64 "24^Deg" 32 "12^Deg" 0 "0^Deg";
VAL_ 552 AGS_LINResponse_Error 1 "ERROR" 0 "NO_ERROR";
VAL_ 552 AGS_Calibration_Enabled 1 "CALIB_ENABLE" 0 "NO_CALIB";
VAL_ 552 AGS_Position_Request 208 "78¢X" 240 "90¢X" 176 "66¢X" 144 "54¢X" 112 "42¢X" 80 "30¢X" 48 "18¢X" 16 "6¢X" 224 "84¢X" 192 "72¢X" 160 "60¢X" 128 "48¢X" 96 "36¢X" 64 "24¢X" 32 "12¢X" 0 "0¢X";
VAL_ 496 SysPwrSta 10 "ON_HVChrg" 9 "OFF-C_LVChrg" 8 "HVChrgPre-action" 7 "Power_down" 6 "Power_up" 5 "READY" 4 "ON_NoChrg" 3 "STANDBY" 2 "OFF-A" 1 "OFF-C_HVChrg" 0 "OFF";
VAL_ 496 PowerUpState 9 "HVSysChk" 8 "DriverSafetyChk" 7 "SafetyChk" 6 "PowerUpFail" 5 "Completed" 4 "MCU_Enable" 3 "OBC_Enable" 2 "DCDC_Enable" 1 "BattPACK" 0 "Initialize";
VAL_ 496 PowerUpFault 8 "DCDC_SetVoltFail" 7 "DriverSafetyChkFail" 6 "SafetyChkFail" 5 "MCU_EnableFail" 4 "OBC_EnableFail" 3 "DCDC_EnableFail" 2 "BattUpFail" 1 "PreChargeChkFail" 0 "No Fault";
VAL_ 496 PowerDownState 7 "MCU_Disable" 6 "MLvSafetyChkPowerDown" 5 "Completed" 4 "OBC_Disable" 3 "MCU_DisCharge" 2 "BattPACK" 1 "DCDC Disable" 0 "Initialize";
VAL_ 496 PowerDownFault 7 "SafetyChkMLvFail" 6 "MCU_Disable" 5 "MCU_Discharge" 4 "BattPDFail" 3 "OBC_Disable" 2 "DCDC_Stop" 1 "DCDC_Disable" 0 "No Fault";
VAL_ 496 PwrStaSelect 3 "Go OFF-A" 2 "Go OFF-C" 1 "Go ON" 0 "No request";
VAL_ 496 PwrStaConstraint 4 "Keep HV active for time" 3 "Keep power state ON for time" 2 "Keep HV active" 1 "Power state ON" 0 "No request";
VAL_ 496 TCountSta 2 "Counting finish" 1 "Timmer counting" 0 "No counting";
VAL_ 496 PwrUpReq 2 "System request  power up" 1 "User request  power up" 0 "No request";
VAL_ 496 PwrDownReq 2 "System request  power down" 1 "User request  power down" 0 "No request";
VAL_ 496 Rr_TqSource 9 "ForceIdle" 8 "APS" 7 "MSA" 6 "ADAS" 5 "CC" 4 "TCS" 3 "RollABS" 2 "ABS" 1 "Internal" 0 "Invalid";
VAL_ 496 Fr_TqSource 9 "ForceIdle" 8 "APS" 7 "MSA" 6 "ADAS" 5 "CC" 4 "TCS" 3 "RollABS" 2 "ABS" 1 "Internal" 0 "Invalid";
VAL_ 496 LVBattVoltSta 3 "Invalid" 2 "Reserved" 1 "Failure" 0 "Normal";
VAL_ 496 HVTHCMSysAvail 3 "Invalid" 2 "Reserved" 1 "Failure" 0 "Normal";
VAL_ 496 VCUBrkSWSta 2 "Invalid" 1 "On" 0 "OFF";
VAL_ 496 VCUFLDoorSta 1 "Fail" 0 "Normal";
VAL_ 496 VCUFRDoorSta 1 "Fail" 0 "Normal";
VAL_ 496 VCURLDoorSta 1 "Fail" 0 "Normal";
VAL_ 496 VCURRDoorSta 1 "Fail" 0 "Normal";
VAL_ 496 SysAllowReadySta 1 "Not allow ready" 0 "Normal";
VAL_ 496 HVRlyOpFail 1 "Fail" 0 "Normal";
VAL_ 496 MCUActDisFail 1 "Fail" 0 "Normal";
VAL_ 496 PwrStaONTOIVIPopReq 1 "On" 0 "OFF";
VAL_ 496 PwrStaTOSta 1 "Timeout" 0 "Normal";
VAL_ 496 SchedChgTOSta 1 "Timeout" 0 "Normal";
VAL_ 496 SilentChkAllowSleep 1 "Allow sleep" 0 "Not allow sleep";
VAL_ 496 LVSilentChrgSta 3 "Fault" 2 "Charging completed" 1 "Charging" 0 "No action";
VAL_ 496 LVSilentChrgLv 3 "Level 3" 2 "Level 2" 1 "Level 1" 0 "Invalid";
VAL_ 496 LVSilentChrgReq 1 "Request LV silent charging" 0 "No request,";
VAL_ 496 TimerAllowSleep 1 "Allow sleep" 0 "Not allow sleep";
VAL_ 496 PMMAllowECUSleep 1 "Allow sleep" 0 "Not allow sleep";
VAL_ 496 EVCCAplusPwrUpReq 1 "Request" 0 "No Request";
VAL_ 496 FDC_VCU_DTCCarousel_Sta 87 "P100A19" 86 "P100A18" 85 "P100A17" 84 "P100A16" 83 "P100A15" 82 "P100A14" 81 "P100A13" 80 "P100A12" 79 "P100A11" 78 "P100A10" 77 "U100A0F" 76 "U100A0E" 75 "U100A0D" 74 "U100A0C" 73 "U100A0B" 72 "U100A0A" 71 "U100A09" 70 "U100A08" 69 "U100A07" 68 "U100A06" 67 "U100A05" 66 "U100A04" 65 "U100A03" 64 "U100A02" 63 "U100A01" 62 "P100252" 61 "P100251" 60 "P100250" 59 "P100249" 58 "P100246" 57 "P100245" 56 "P100244" 55 "P100243" 54 "P100242" 53 "U100241" 52 "U100240" 51 "U10023F" 50 "U10023E" 49 "U10023D" 48 "U10023C" 47 "U10023B" 46 "U10023A" 45 "U100239" 44 "U100238" 43 "U100237" 42 "U100236" 41 "U100235" 40 "U100234" 39 "U100233" 38 "U100232" 37 "U100231" 36 "U100230" 35 "B10022F" 34 "B10022E" 33 "U10022D" 32 "U10022C" 31 "U10022B" 30 "U10022A" 29 "U100229" 28 "U100228" 27 "P100227" 26 "P100226" 25 "P100225" 24 "P100224" 23 "P100223" 22 "P100221" 21 "P100220" 20 "B10021F" 19 "P10021E" 18 "P10021D" 17 "P10021C" 16 "P10021B" 15 "P10021A" 14 "P100219" 13 "P100218" 12 "P100217" 11 "P100216" 10 "P100215" 9 "P100214" 8 "P100213" 7 "P100212" 6 "P100211" 5 "P100210" 4 "P10020E" 3 "P10020D" 2 "P10020C" 1 "P10020B" 0 "0";
VAL_ 496 FDC_VCU_VehMalfunLevel_Sta 5 "Invalid" 4 "4th grade malfunction" 3 "3rd grade malfunction" 2 "2nd grade malfunction" 1 "1st grade malfunction" 0 "Normal";
VAL_ 496 FDC_VCU_RWDRDCActive_Sta 2 "Exit immediately" 1 "Ramp out" 0 "No request";
VAL_ 496 FDC_VCU_AllowMovThd_OTA_Sta 2 "Invalid" 1 "Not allow to ready" 0 "Allow to ready";
VAL_ 496 FDC_VCU_PwrReq_OTA_Sta 3 "Request power STANDBY" 2 "Request power OFF" 1 "Request power ON" 0 "No request";
VAL_ 496 FDC_VCU_RegenTqLimitEn_Sta 1 "Enable" 0 "Disable";
VAL_ 496 FDC_VCU_ForceP_Cmd 1 "On" 0 "Off";
VAL_ 496 FDC_VMC_AntiSpdLimEn_Sta 1 "ON" 0 "OFF";
